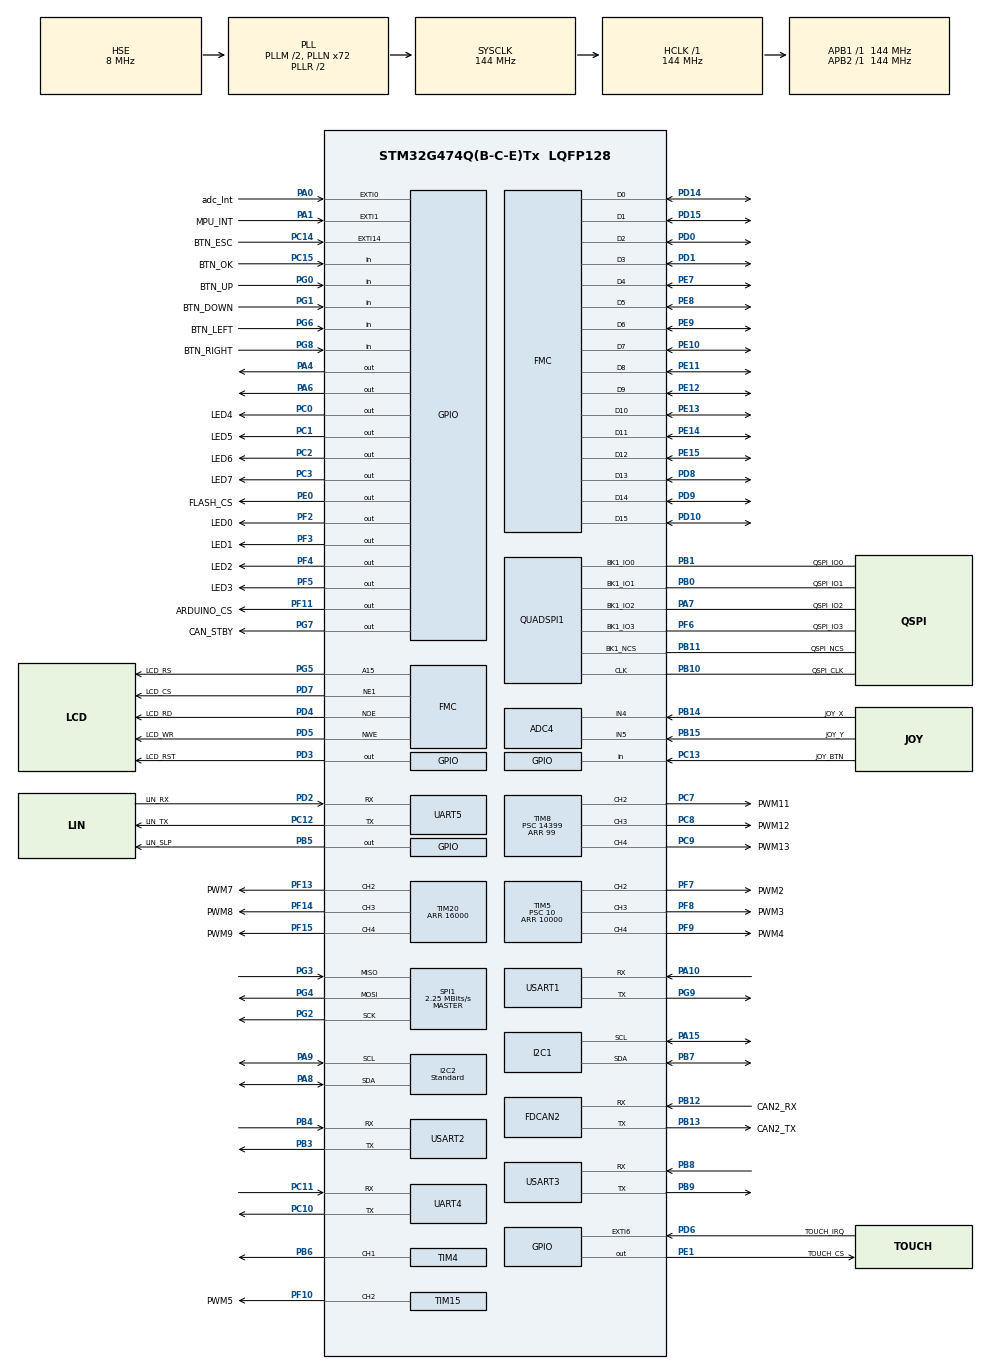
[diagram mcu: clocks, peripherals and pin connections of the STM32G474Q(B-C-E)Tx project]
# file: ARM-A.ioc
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ADC4.Channel-0\#ChannelRegularConversion=ADC_CHANNEL_4
ADC4.Channel-1\#ChannelRegularConversion=ADC_CHANNEL_5
ADC4.ClockPrescaler=ADC_CLOCK_ASYNC_DIV4
ADC4.ContinuousConvMode=DISABLE
ADC4.DMAContinuousRequests=ENABLE
ADC4.DiscontinuousConvMode=DISABLE
ADC4.EOCSelection=ADC_EOC_SINGLE_CONV
ADC4.ExternalTrigConv=ADC_EXTERNALTRIG_T1_TRGO
ADC4.NbrOfConversion=2
ADC4.NbrOfConversionFlag=1
ADC4.OffsetNumber-0\#ChannelRegularConversion=ADC_OFFSET_NONE
ADC4.OffsetNumber-1\#ChannelRegularConversion=ADC_OFFSET_NONE
ADC4.Overrun=ADC_OVR_DATA_PRESERVED
ADC4.Rank-0\#ChannelRegularConversion=1
ADC4.Rank-1\#ChannelRegularConversion=2
ADC4.SamplingTime-0\#ChannelRegularConversion=ADC_SAMPLETIME_640CYCLES_5
ADC4.SamplingTime-1\#ChannelRegularConversion=ADC_SAMPLETIME_640CYCLES_5
Dma.ADC4.2.Direction=DMA_PERIPH_TO_MEMORY
Dma.ADC4.2.EventEnable=DISABLE
Dma.ADC4.2.Instance=DMA1_Channel1
Dma.ADC4.2.MemDataAlignment=DMA_MDATAALIGN_HALFWORD
Dma.ADC4.2.MemInc=DMA_MINC_ENABLE
Dma.ADC4.2.Mode=DMA_CIRCULAR
Dma.ADC4.2.PeriphDataAlignment=DMA_PDATAALIGN_HALFWORD
Dma.ADC4.2.PeriphInc=DMA_PINC_DISABLE
Dma.ADC4.2.Polarity=HAL_DMAMUX_REQ_GEN_RISING
Dma.ADC4.2.Priority=DMA_PRIORITY_LOW
Dma.ADC4.2.RequestNumber=1
Dma.ADC4.2.SignalID=NONE
Dma.ADC4.2.SyncEnable=DISABLE
Dma.ADC4.2.SyncPolarity=HAL_DMAMUX_SYNC_NO_EVENT
Dma.ADC4.2.SyncRequestNumber=1
Dma.ADC4.2.SyncSignalID=NONE
Dma.Request0=USART1_RX
Dma.Request1=USART1_TX
Dma.Request2=ADC4
Dma.Request3=SPI1_RX
Dma.Request4=SPI1_TX
Dma.SPI1_RX.3.Direction=DMA_PERIPH_TO_MEMORY
Dma.SPI1_RX.3.EventEnable=DISABLE
Dma.SPI1_RX.3.Instance=DMA1_Channel4
Dma.SPI1_RX.3.MemDataAlignment=DMA_MDATAALIGN_BYTE
Dma.SPI1_RX.3.MemInc=DMA_MINC_ENABLE
Dma.SPI1_RX.3.Mode=DMA_NORMAL
Dma.SPI1_RX.3.PeriphDataAlignment=DMA_PDATAALIGN_BYTE
Dma.SPI1_RX.3.PeriphInc=DMA_PINC_DISABLE
Dma.SPI1_RX.3.Polarity=HAL_DMAMUX_REQ_GEN_RISING
Dma.SPI1_RX.3.Priority=DMA_PRIORITY_LOW
Dma.SPI1_RX.3.RequestNumber=1
Dma.SPI1_RX.3.SignalID=NONE
Dma.SPI1_RX.3.SyncEnable=DISABLE
Dma.SPI1_RX.3.SyncPolarity=HAL_DMAMUX_SYNC_NO_EVENT
Dma.SPI1_RX.3.SyncRequestNumber=1
Dma.SPI1_RX.3.SyncSignalID=NONE
Dma.SPI1_TX.4.Direction=DMA_MEMORY_TO_PERIPH
Dma.SPI1_TX.4.EventEnable=DISABLE
Dma.SPI1_TX.4.Instance=DMA1_Channel5
Dma.SPI1_TX.4.MemDataAlignment=DMA_MDATAALIGN_BYTE
Dma.SPI1_TX.4.MemInc=DMA_MINC_ENABLE
Dma.SPI1_TX.4.Mode=DMA_NORMAL
Dma.SPI1_TX.4.PeriphDataAlignment=DMA_PDATAALIGN_BYTE
Dma.SPI1_TX.4.PeriphInc=DMA_PINC_DISABLE
Dma.SPI1_TX.4.Polarity=HAL_DMAMUX_REQ_GEN_RISING
Dma.SPI1_TX.4.Priority=DMA_PRIORITY_LOW
Dma.SPI1_TX.4.RequestNumber=1
Dma.SPI1_TX.4.SignalID=NONE
Dma.SPI1_TX.4.SyncEnable=DISABLE
Dma.SPI1_TX.4.SyncPolarity=HAL_DMAMUX_SYNC_NO_EVENT
Dma.SPI1_TX.4.SyncRequestNumber=1
Dma.SPI1_TX.4.SyncSignalID=NONE
Dma.USART1_RX.0.Direction=DMA_PERIPH_TO_MEMORY
Dma.USART1_RX.0.EventEnable=DISABLE
Dma.USART1_RX.0.Instance=DMA1_Channel3
Dma.USART1_RX.0.MemDataAlignment=DMA_MDATAALIGN_BYTE
Dma.USART1_RX.0.MemInc=DMA_MINC_ENABLE
Dma.USART1_RX.0.Mode=DMA_NORMAL
Dma.USART1_RX.0.PeriphDataAlignment=DMA_PDATAALIGN_BYTE
Dma.USART1_RX.0.PeriphInc=DMA_PINC_DISABLE
Dma.USART1_RX.0.Polarity=HAL_DMAMUX_REQ_GEN_RISING
Dma.USART1_RX.0.Priority=DMA_PRIORITY_LOW
Dma.USART1_RX.0.RequestNumber=1
Dma.USART1_RX.0.SignalID=NONE
Dma.USART1_RX.0.SyncEnable=DISABLE
Dma.USART1_RX.0.SyncPolarity=HAL_DMAMUX_SYNC_NO_EVENT
Dma.USART1_RX.0.SyncRequestNumber=1
Dma.USART1_RX.0.SyncSignalID=NONE
Dma.USART1_TX.1.Direction=DMA_MEMORY_TO_PERIPH
Dma.USART1_TX.1.EventEnable=DISABLE
Dma.USART1_TX.1.Instance=DMA1_Channel2
Dma.USART1_TX.1.MemDataAlignment=DMA_MDATAALIGN_BYTE
Dma.USART1_TX.1.MemInc=DMA_MINC_ENABLE
Dma.USART1_TX.1.Mode=DMA_NORMAL
Dma.USART1_TX.1.PeriphDataAlignment=DMA_PDATAALIGN_BYTE
Dma.USART1_TX.1.PeriphInc=DMA_PINC_DISABLE
Dma.USART1_TX.1.Polarity=HAL_DMAMUX_REQ_GEN_RISING
Dma.USART1_TX.1.Priority=DMA_PRIORITY_LOW
Dma.USART1_TX.1.RequestNumber=1
Dma.USART1_TX.1.SignalID=NONE
Dma.USART1_TX.1.SyncEnable=DISABLE
Dma.USART1_TX.1.SyncPolarity=HAL_DMAMUX_SYNC_NO_EVENT
Dma.USART1_TX.1.SyncRequestNumber=1
Dma.USART1_TX.1.SyncSignalID=NONE
FDCAN2.CalculateBaudRateNominal=1800000
FDCAN2.CalculateTimeBitNominal=555
FDCAN2.CalculateTimeQuantumNominal=111.11111111111111
FMC.AddressSetupTime1=3
FMC.BusTurnAroundDuration1=3
FMC.DataHoldTime1=3
FMC.DataSetupTime1=3
FMC.ExtendedMode1=FMC_EXTENDED_MODE_DISABLE
I2C1.Timing=0x60715075
I2C2.I2C_Speed_Mode=I2C_Standard
I2C2.Timing=0x60715075
Mcu.Family=STM32G4
Mcu.Name=STM32G474Q(B-C-E)Tx
Mcu.Package=LQFP128
NVIC.DMA1_Channel1_IRQn=true\:0\:0\:false\:false\:true\:false\:true\:true
NVIC.DMA1_Channel2_IRQn=true\:0\:0\:false\:false\:true\:false\:true\:true
NVIC.DMA1_Channel3_IRQn=true\:0\:0\:false\:false\:true\:false\:true\:true
NVIC.DMA1_Channel4_IRQn=true\:0\:0\:false\:false\:true\:false\:true\:true
NVIC.DMA1_Channel5_IRQn=true\:0\:0\:false\:false\:true\:false\:true\:true
NVIC.EXTI0_IRQn=true\:1\:0\:true\:false\:true\:true\:true\:true
NVIC.EXTI15_10_IRQn=true\:0\:0\:true\:false\:true\:true\:true\:true
NVIC.EXTI1_IRQn=true\:1\:0\:true\:false\:true\:true\:true\:true
NVIC.EXTI9_5_IRQn=true\:0\:0\:false\:false\:true\:true\:true\:true
NVIC.PriorityGroup=NVIC_PRIORITYGROUP_4
NVIC.TIM6_DAC_IRQn=true\:0\:0\:false\:false\:true\:true\:true\:true
NVIC.USART3_IRQn=true\:0\:0\:false\:false\:true\:true\:true\:true
PA0.GPIO_Label=adc_Int
PA0.GPIO_ModeDefaultEXTI=GPIO_MODE_IT_FALLING
PA0.GPIO_PuPd=GPIO_PULLUP
PA0.Signal=GPXTI0
PA1.GPIO_Label=MPU_INT
PA1.GPIO_ModeDefaultEXTI=GPIO_MODE_IT_FALLING
PA1.Signal=GPXTI1
PA10.Mode=Asynchronous
PA10.Signal=USART1_RX
PA11.GPIO_Label=USB_MCU_N
PA11.Signal=USB_DM
PA12.GPIO_Label=USB_MCU_P
PA12.Signal=USB_DP
PA13.GPIO_Label=SWDIO
PA13.Mode=Trace_Synchro_4bits_SW
PA13.Signal=SYS_JTMS-SWDIO
PA14.GPIO_Label=SWCLK
PA14.Mode=Trace_Synchro_4bits_SW
PA14.Signal=SYS_JTCK-SWCLK
PA15.Mode=I2C
PA15.Signal=I2C1_SCL
PA2.GPIO_Label=AD2
PA2.Signal=ADC1_IN3
PA3.GPIO_Label=AD3
PA3.Signal=ADC1_IN4
PA4.Signal=GPIO_Output
PA5.GPIO_Label=AD8
PA5.Signal=ADC2_IN13
PA6.Signal=GPIO_Output
PA7.GPIO_Label=QSPI_IO2
PA7.GPIO_Speed=GPIO_SPEED_FREQ_VERY_HIGH
PA7.Mode=Single Bank 1
PA7.Signal=QUADSPI1_BK1_IO2
PA8.GPIO_Pu=GPIO_PULLUP
PA8.Mode=I2C
PA8.Signal=I2C2_SDA
PA9.GPIO_Pu=GPIO_PULLUP
PA9.Mode=I2C
PA9.Signal=I2C2_SCL
PB0.GPIO_Label=QSPI_IO1
PB0.GPIO_Speed=GPIO_SPEED_FREQ_VERY_HIGH
PB0.Mode=Single Bank 1
PB0.Signal=QUADSPI1_BK1_IO1
PB1.GPIO_Label=QSPI_IO0
PB1.GPIO_Speed=GPIO_SPEED_FREQ_VERY_HIGH
PB1.Mode=Single Bank 1
PB1.Signal=QUADSPI1_BK1_IO0
PB10.GPIO_Label=QSPI_CLK
PB10.GPIO_Speed=GPIO_SPEED_FREQ_VERY_HIGH
PB10.Mode=Single Bank 1
PB10.Signal=QUADSPI1_CLK
PB11.GPIO_Label=QSPI_NCS
PB11.GPIO_Speed=GPIO_SPEED_FREQ_VERY_HIGH
PB11.Mode=Single Bank 1
PB11.Signal=QUADSPI1_BK1_NCS
PB12.GPIO_Label=CAN2_RX
PB12.Mode=FDCAN_Activate
PB12.Signal=FDCAN2_RX
PB13.GPIO_Label=CAN2_TX
PB13.Mode=FDCAN_Activate
PB13.Signal=FDCAN2_TX
PB14.GPIO_Label=JOY_X
PB14.Mode=IN4-Single-Ended
PB14.Signal=ADC4_IN4
PB15.GPIO_Label=JOY_Y
PB15.Mode=IN5-Single-Ended
PB15.Signal=ADC4_IN5
PB3.Mode=Asynchronous
PB3.Signal=USART2_TX
PB4.Mode=Asynchronous
PB4.Signal=USART2_RX
PB5.GPIO_Label=LIN_SLP
PB5.Signal=GPIO_Output
PB6.Signal=S_TIM4_CH1
PB7.Mode=I2C
PB7.Signal=I2C1_SDA
PB8-BOOT0.Mode=Asynchronous
PB8-BOOT0.Signal=USART3_RX
PB9.Mode=Asynchronous
PB9.Signal=USART3_TX
PC0.GPIO_Label=LED4
PC0.Signal=GPIO_Output
PC1.GPIO_Label=LED5
PC1.Signal=GPIO_Output
PC10.Mode=Asynchronous
PC10.Signal=UART4_TX
PC11.Mode=Asynchronous
PC11.Signal=UART4_RX
PC12.GPIO_Label=LIN_TX
PC12.Mode=Asynchronous
PC12.Signal=UART5_TX
PC13.GPIO_Label=JOY_BTN
PC13.GPIO_PuPd=GPIO_PULLUP
PC13.Signal=GPIO_Input
PC14-OSC32_IN.GPIO_Label=BTN_ESC
PC14-OSC32_IN.GPIO_ModeDefaultEXTI=GPIO_MODE_IT_FALLING
PC14-OSC32_IN.GPIO_PuPd=GPIO_PULLUP
PC14-OSC32_IN.Signal=GPXTI14
PC15-OSC32_OUT.GPIO_Label=BTN_OK
PC15-OSC32_OUT.GPIO_PuPd=GPIO_PULLUP
PC15-OSC32_OUT.Signal=GPIO_Input
PC2.GPIO_Label=LED6
PC2.Signal=GPIO_Output
PC3.GPIO_Label=LED7
PC3.Signal=GPIO_Output
PC4.GPIO_Label=AD4
PC4.Signal=ADC2_IN5
PC5.GPIO_Label=AD6
PC5.Signal=ADC2_IN11
PC7.GPIO_Label=PWM11
PC7.Signal=S_TIM8_CH2
PC8.GPIO_Label=PWM12
PC8.Signal=S_TIM8_CH3
PC9.GPIO_Label=PWM13
PC9.Signal=S_TIM8_CH4
PD0.Signal=FMC_D2_DA2
PD1.Signal=FMC_D3_DA3
PD10.Signal=FMC_D15_DA15
PD11.GPIO_Label=AD9
PD11.GPIO_Mode=GPIO_MODE_ANALOG
PD11.GPIO_PuPd=GPIO_NOPULL
PD11.Signal=ADC3_IN8
PD12.GPIO_Label=AD10
PD12.GPIO_Mode=GPIO_MODE_ANALOG
PD12.GPIO_PuPd=GPIO_NOPULL
PD12.Signal=ADC3_IN9
PD13.GPIO_Label=AD11
PD13.GPIO_Mode=GPIO_MODE_ANALOG
PD13.GPIO_PuPd=GPIO_NOPULL
PD13.Signal=ADC3_IN10
PD14.Signal=FMC_D0_DA0
PD15.Signal=FMC_D1_DA1
PD2.GPIO_Label=LIN_RX
PD2.Mode=Asynchronous
PD2.Signal=UART5_RX
PD3.GPIO_Label=LCD_RST
PD3.Signal=GPIO_Output
PD4.GPIO_Label=LCD_RD
PD4.Signal=FMC_NOE
PD5.GPIO_Label=LCD_WR
PD5.Signal=FMC_NWE
PD6.GPIO_Label=TOUCH_IRQ
PD6.GPIO_ModeDefaultEXTI=GPIO_MODE_IT_FALLING
PD6.GPIO_PuPd=GPIO_PULLUP
PD6.Signal=GPXTI6
PD7.GPIO_Label=LCD_CS
PD7.Mode=NorPsramChipSelect1_1
PD7.Signal=FMC_NE1
PD8.Signal=FMC_D13_DA13
PD9.Signal=FMC_D14_DA14
PE0.GPIO_Label=FLASH_CS
PE0.Signal=GPIO_Output
PE1.GPIO_Label=TOUCH_CS
PE1.GPIO_PuPd=GPIO_PULLUP
PE1.GPIO_Speed=GPIO_SPEED_FREQ_HIGH
PE1.PinState=GPIO_PIN_SET
PE1.Signal=GPIO_Output
PE10.Signal=FMC_D7_DA7
PE11.Signal=FMC_D8_DA8
PE12.Signal=FMC_D9_DA9
PE13.Signal=FMC_D10_DA10
PE14.Signal=FMC_D11_DA11
PE15.Signal=FMC_D12_DA12
PE2.Mode=Trace_Synchro_4bits_SW
PE2.Signal=SYS_TRACECLK
PE3.Mode=Trace_Synchro_4bits_SW
PE3.Signal=SYS_TRACED0
PE4.Mode=Trace_Synchro_4bits_SW
PE4.Signal=SYS_TRACED1
PE5.Mode=Trace_Synchro_4bits_SW
PE5.Signal=SYS_TRACED2
PE6.Mode=Trace_Synchro_4bits_SW
PE6.Signal=SYS_TRACED3
PE7.Signal=FMC_D4_DA4
PE8.Signal=FMC_D5_DA5
PE9.Signal=FMC_D6_DA6
PF0-OSC_IN.GPIO_Label=MCI
PF0-OSC_IN.Mode=HSE-External-Clock-Source
PF0-OSC_IN.Signal=RCC_OSC_IN
PF1-OSC_OUT.GPIO_Label=AD5
PF1-OSC_OUT.Signal=ADC2_IN10
PF10.GPIO_Label=PWM5
PF10.Signal=S_TIM15_CH2
PF11.GPIO_Label=ARDUINO_CS
PF11.Signal=GPIO_Output
PF12.GPIO_Label=PWM6
PF12.Signal=S_TIM20_CH1
PF13.GPIO_Label=PWM7
PF13.Signal=S_TIM20_CH2
PF14.GPIO_Label=PWM8
PF14.Signal=S_TIM20_CH3
PF15.GPIO_Label=PWM9
PF15.Signal=S_TIM20_CH4
PF2.GPIO_Label=LED0
PF2.GPIO_Speed=GPIO_SPEED_FREQ_VERY_HIGH
PF2.Signal=GPIO_Output
PF3.GPIO_Label=LED1
PF3.Signal=GPIO_Output
PF4.GPIO_Label=LED2
PF4.Signal=GPIO_Output
PF5.GPIO_Label=LED3
PF5.Signal=GPIO_Output
PF6.GPIO_Label=QSPI_IO3
PF6.GPIO_Speed=GPIO_SPEED_FREQ_VERY_HIGH
PF6.Mode=Single Bank 1
PF6.Signal=QUADSPI1_BK1_IO3
PF7.GPIO_Label=PWM2
PF7.Signal=S_TIM5_CH2
PF8.GPIO_Label=PWM3
PF8.Signal=S_TIM5_CH3
PF9.GPIO_Label=PWM4
PF9.Signal=S_TIM5_CH4
PG0.GPIO_Label=BTN_UP
PG0.GPIO_PuPd=GPIO_PULLUP
PG0.Signal=GPIO_Input
PG1.GPIO_Label=BTN_DOWN
PG1.GPIO_PuPd=GPIO_PULLUP
PG1.Signal=GPIO_Input
PG2.Mode=Full_Duplex_Master
PG2.Signal=SPI1_SCK
PG3.Mode=Full_Duplex_Master
PG3.Signal=SPI1_MISO
PG4.Mode=Full_Duplex_Master
PG4.Signal=SPI1_MOSI
PG5.GPIO_Label=LCD_RS
PG5.Signal=FMC_A15
PG6.GPIO_Label=BTN_LEFT
PG6.GPIO_PuPd=GPIO_PULLUP
PG6.Signal=GPIO_Input
PG7.GPIO_Label=CAN_STBY
PG7.Signal=GPIO_Output
PG8.GPIO_Label=BTN_RIGHT
PG8.GPIO_PuPd=GPIO_PULLUP
PG8.Signal=GPIO_Input
PG9.Mode=Asynchronous
PG9.Signal=USART1_TX
ProjectManager.HeapSize=0x200
ProjectManager.StackSize=0x400
ProjectManager.TargetToolchain=STM32CubeIDE
QUADSPI1.ChipSelectHighTime=QSPI_CS_HIGH_TIME_6_CYCLE
QUADSPI1.FifoThreshold=4
QUADSPI1.FlashSize=23
QUADSPI1.SampleShifting=QSPI_SAMPLE_SHIFTING_HALFCYCLE
RCC.ADC12Freq_Value=144000000
RCC.ADC345Freq_Value=144000000
RCC.AHBFreq_Value=144000000
RCC.APB1Freq_Value=144000000
RCC.APB1TimFreq_Value=144000000
RCC.APB2Freq_Value=144000000
RCC.APB2TimFreq_Value=144000000
RCC.CortexFreq_Value=144000000
RCC.EXTERNAL_CLOCK_VALUE=12288000
RCC.HCLKFreq_Value=144000000
RCC.HSE_VALUE=8000000
RCC.HSI48_VALUE=48000000
RCC.HSI_VALUE=16000000
RCC.LSE_VALUE=32768
RCC.PLLM=RCC_PLLM_DIV2
RCC.PLLN=72
RCC.PLLQ=RCC_PLLQ_DIV6
RCC.PLLSourceVirtual=RCC_PLLSOURCE_HSE
RCC.SYSCLKFreq_VALUE=144000000
RCC.SYSCLKSource=RCC_SYSCLKSOURCE_PLLCLK
RCC.USBFreq_Value=48000000
RCC.VCOOutputFreq_Value=288000000
SH.FMC_A15.0=FMC_A15,A15_1
SH.FMC_D0_DA0.0=FMC_D0,16b-d1
SH.FMC_D10_DA10.0=FMC_D10,16b-d1
SH.FMC_D11_DA11.0=FMC_D11,16b-d1
SH.FMC_D12_DA12.0=FMC_D12,16b-d1
SH.FMC_D13_DA13.0=FMC_D13,16b-d1
SH.FMC_D14_DA14.0=FMC_D14,16b-d1
SH.FMC_D15_DA15.0=FMC_D15,16b-d1
SH.FMC_D1_DA1.0=FMC_D1,16b-d1
SH.FMC_D2_DA2.0=FMC_D2,16b-d1
SH.FMC_D3_DA3.0=FMC_D3,16b-d1
SH.FMC_D4_DA4.0=FMC_D4,16b-d1
SH.FMC_D5_DA5.0=FMC_D5,16b-d1
SH.FMC_D6_DA6.0=FMC_D6,16b-d1
SH.FMC_D7_DA7.0=FMC_D7,16b-d1
SH.FMC_D8_DA8.0=FMC_D8,16b-d1
SH.FMC_D9_DA9.0=FMC_D9,16b-d1
SH.FMC_NOE.0=FMC_NOE,Lcd1
SH.FMC_NWE.0=FMC_NWE,Lcd1
SH.S_TIM15_CH2.0=TIM15_CH2,PWM Generation2 CH2
SH.S_TIM20_CH1.0=TIM20_CH1
SH.S_TIM20_CH2.0=TIM20_CH2,PWM Generation2 CH2
SH.S_TIM20_CH3.0=TIM20_CH3,PWM Generation3 CH3
SH.S_TIM20_CH4.0=TIM20_CH4,PWM Generation4 CH4
SH.S_TIM4_CH1.0=TIM4_CH1,PWM Generation1 CH1
SH.S_TIM5_CH2.0=TIM5_CH2,PWM Generation2 CH2
SH.S_TIM5_CH3.0=TIM5_CH3,PWM Generation3 CH3
SH.S_TIM5_CH4.0=TIM5_CH4,PWM Generation4 CH4
SH.S_TIM8_CH2.0=TIM8_CH2,PWM Generation2 CH2
SH.S_TIM8_CH3.0=TIM8_CH3,PWM Generation3 CH3
SH.S_TIM8_CH4.0=TIM8_CH4,PWM Generation4 CH4
SPI1.BaudRatePrescaler=SPI_BAUDRATEPRESCALER_64
SPI1.CalculateBaudRate=2.25 MBits/s
SPI1.DataSize=SPI_DATASIZE_8BIT
SPI1.Direction=SPI_DIRECTION_2LINES
SPI1.Mode=SPI_MODE_MASTER
SPI1.NSSPMode=SPI_NSS_PULSE_DISABLE
SPI1.VirtualType=VM_MASTER
STMicroelectronics.X-CUBE-DISPLAY.2.0.0.BSP.number=2
STMicroelectronics.X-CUBE-DISPLAY.2.0.0.p_display_cache_lines=4
STMicroelectronics.X-CUBE-DISPLAY.2.0.0.p_fmc_dma_tx_id=1\:1
STMicroelectronics.X-CUBE-DISPLAY.2.0.00.BSP.STBoard=false
STMicroelectronics.X-CUBE-DISPLAY.2.0.00.BSP.api=Unknown
STMicroelectronics.X-CUBE-DISPLAY.2.0.00.BSP.condition=(SEMBoardOoPartJjLCDJjILI9341JjSPI | SEMBoardOoPartJjLCDJjILI9341JjFMC)
STMicroelectronics.X-CUBE-DISPLAY.2.0.00.BSP.instance=PD3
STMicroelectronics.X-CUBE-DISPLAY.2.0.00.BSP.ip=GPIO
STMicroelectronics.X-CUBE-DISPLAY.2.0.00.BSP.mode=Output
STMicroelectronics.X-CUBE-DISPLAY.2.0.00.BSP.name=LCD RESET Pin
STMicroelectronics.X-CUBE-DISPLAY.2.0.00.BSP.solution=PD3
STMicroelectronics.X-CUBE-DISPLAY.2.0.01.BSP.STBoard=false
STMicroelectronics.X-CUBE-DISPLAY.2.0.01.BSP.api=HAL_EXTI_DRIVER
STMicroelectronics.X-CUBE-DISPLAY.2.0.01.BSP.condition=(SEMBoardOoPartJjLCDJjILI9341JjSPI | SEMBoardOoPartJjLCDJjILI9341JjFMC)
STMicroelectronics.X-CUBE-DISPLAY.2.0.01.BSP.instance=PC14-OSC32_IN
STMicroelectronics.X-CUBE-DISPLAY.2.0.01.BSP.ip=GPIO
STMicroelectronics.X-CUBE-DISPLAY.2.0.01.BSP.mode=EXTI
STMicroelectronics.X-CUBE-DISPLAY.2.0.01.BSP.name=LCD TE Pin
STMicroelectronics.X-CUBE-DISPLAY.2.0.01.BSP.solution=PC14-OSC32_IN
STMicroelectronics.X-CUBE-TOUCHGFX.4.18.0.tgfx_buffering_strategy=Partial
STMicroelectronics.X-CUBE-TOUCHGFX.4.18.0.tgfx_custom_height=240
STMicroelectronics.X-CUBE-TOUCHGFX.4.18.0.tgfx_custom_width=320
STMicroelectronics.X-CUBE-TOUCHGFX.4.18.0.tgfx_display_interface=disp_fmc
STMicroelectronics.X-CUBE-TOUCHGFX.4.18.0.tgfx_hardware_accelerator=dma_none
STMicroelectronics.X-CUBE-TOUCHGFX.4.18.0_IsPackSelfContextualization=true
TIM1.PeriodNoDither=9999
TIM1.Prescaler=144
TIM1.TIM_MasterOutputTrigger=TIM_TRGO_UPDATE
TIM15.Channel-PWM\ Generation2\ CH2=TIM_CHANNEL_2
TIM15.PeriodNoDither=32768
TIM15.PulseNoDither_2=16000
TIM20.Channel-PWM\ Generation1\ CH1=TIM_CHANNEL_1
TIM20.Channel-PWM\ Generation2\ CH2=TIM_CHANNEL_2
TIM20.Channel-PWM\ Generation3\ CH3=TIM_CHANNEL_3
TIM20.Channel-PWM\ Generation4\ CH4=TIM_CHANNEL_4
TIM20.PeriodNoDither=16000
TIM20.PulseNoDither_1=8000
TIM20.PulseNoDither_2=10000
TIM20.PulseNoDither_3=12000
TIM20.PulseNoDither_4=15000
TIM4.Channel-PWM\ Generation1\ CH1=TIM_CHANNEL_1
TIM4.OC1Preload_PWM=DISABLE
TIM4.OCPolarity_1=TIM_OCPOLARITY_LOW
TIM4.PeriodNoDither=99
TIM4.Prescaler=14399
TIM4.PulseNoDither_1=50
TIM5.AutoReloadPreload=TIM_AUTORELOAD_PRELOAD_ENABLE
TIM5.Channel-PWM\ Generation2\ CH2=TIM_CHANNEL_2
TIM5.Channel-PWM\ Generation3\ CH3=TIM_CHANNEL_3
TIM5.Channel-PWM\ Generation4\ CH4=TIM_CHANNEL_4
TIM5.PeriodNoDither=10000
TIM5.Prescaler=10
TIM5.PulseNoDither_2=200
TIM5.PulseNoDither_3=400
TIM5.PulseNoDither_4=600
TIM6.AutoReloadPreload=TIM_AUTORELOAD_PRELOAD_ENABLE
TIM6.PeriodNoDither=49999
TIM6.Prescaler=170
TIM8.Channel-PWM\ Generation2\ CH2=TIM_CHANNEL_2
TIM8.Channel-PWM\ Generation3\ CH3=TIM_CHANNEL_3
TIM8.Channel-PWM\ Generation4\ CH4=TIM_CHANNEL_4
TIM8.PeriodNoDither=99
TIM8.Prescaler=14399
TIM8.PulseNoDither_2=2000
TIM8.PulseNoDither_3=4000
TIM8.PulseNoDither_4=8000
USART1.VirtualMode-Asynchronous=VM_ASYNC
USART2.VirtualMode-Asynchronous=VM_ASYNC
USART3.VirtualMode-Asynchronous=VM_ASYNC
VP_CORDIC_VS_CORDIC.Mode=CORDIC_Activate
VP_SYS_VS_DBSignals.Mode=DisableDeadBatterySignals
VP_TIM15_VS_ClockSourceINT.Mode=Internal
VP_TIM1_VS_ClockSourceINT.Mode=Internal
VP_TIM20_VS_ClockSourceINT.Mode=Internal
VP_TIM4_VS_ClockSourceINT.Mode=Internal
VP_TIM5_VS_ClockSourceINT.Mode=Internal
VP_TIM6_VS_ClockSourceINT.Mode=Enable_Timer
VP_TIM8_VS_ClockSourceINT.Mode=Internal
board=custom

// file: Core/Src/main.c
/* USER CODE BEGIN Header */
/**
  ******************************************************************************
  * @file           : main.c
  * @brief          : Main program body
  ******************************************************************************
  * @attention
  *
  * Copyright (c) 2022 STMicroelectronics.
  * All rights reserved.
  *
  * This software is licensed under terms that can be found in the LICENSE file
  * in the root directory of this software component.
  * If no LICENSE file comes with this software, it is provided AS-IS.
  *
  ******************************************************************************
  */
/* USER CODE END Header */
#include "main.h"

/* USER CODE BEGIN Includes */
#include "pca9685.h"
#include "LED.h"
#include "kbd.h"
#include "SCI.h"
#include "lcd.h"
#include "timing_utils.h"
#include "periodic_services.h"
#include "lcd_backlight.h"
#include "XPT2046_touch.h"
#include "3DEngine.h"
#include "joystick.h"
#include "mcp3464.h"
#include "mpu6050.h"
/* USER CODE END Includes */

 ADC_HandleTypeDef hadc4;
DMA_HandleTypeDef hdma_adc4;

CORDIC_HandleTypeDef hcordic;

FDCAN_HandleTypeDef hfdcan2;

I2C_HandleTypeDef hi2c1;
I2C_HandleTypeDef hi2c2;

QSPI_HandleTypeDef hqspi1;

SPI_HandleTypeDef hspi1;
DMA_HandleTypeDef hdma_spi1_rx;
DMA_HandleTypeDef hdma_spi1_tx;

TIM_HandleTypeDef htim1;
TIM_HandleTypeDef htim4;
TIM_HandleTypeDef htim5;
TIM_HandleTypeDef htim6;
TIM_HandleTypeDef htim15;
TIM_HandleTypeDef htim20;

UART_HandleTypeDef huart4;
UART_HandleTypeDef huart5;
UART_HandleTypeDef huart1;
UART_HandleTypeDef huart2;
DMA_HandleTypeDef hdma_usart1_rx;
DMA_HandleTypeDef hdma_usart1_tx;

SRAM_HandleTypeDef hsram1;

void SystemClock_Config(void);
static void MX_GPIO_Init(void);
static void MX_FMC_Init(void);
static void MX_UART4_Init(void);
static void MX_UART5_Init(void);
static void MX_USART1_UART_Init(void);
static void MX_USART2_UART_Init(void);
static void MX_QUADSPI1_Init(void);
static void MX_SPI1_Init(void);
static void MX_TIM5_Init(void);
static void MX_TIM8_Init(void);
static void MX_TIM20_Init(void);
static void MX_FDCAN2_Init(void);
static void MX_I2C1_Init(void);
static void MX_TIM15_Init(void);
static void MX_USART3_UART_Init(void);
static void MX_ADC4_Init(void);
static void MX_DMA_Init(void);
static void MX_TIM6_Init(void);
static void MX_CORDIC_Init(void);
static void MX_TIM1_Init(void);
static void MX_TIM4_Init(void);

int main(void)
{

  /* MCU Configuration--------------------------------------------------------*/

  /* Reset of all peripherals, Initializes the Flash interface and the Systick. */
  HAL_Init();

  /* Configure the system clock */
  SystemClock_Config();

  /* Initialize all configured peripherals */
  MX_GPIO_Init();
  MX_FMC_Init();
  MX_I2C2_Init();
  MX_UART4_Init();
  MX_UART5_Init();
  MX_USART1_UART_Init();
  MX_USART2_UART_Init();
  MX_QUADSPI1_Init();
  MX_SPI1_Init();
  MX_TIM5_Init();
  MX_TIM8_Init();
  MX_TIM20_Init();
  MX_FDCAN2_Init();
  MX_I2C1_Init();
  MX_TIM15_Init();
  MX_USART3_UART_Init();
  MX_DMA_Init();
  MX_TIM6_Init();
  MX_CORDIC_Init();
  MX_TIM1_Init();
  MX_TIM4_Init();
  /* USER CODE BEGIN 2 */
  MX_ADC4_Init();
  MX_SPI1_Init();

  LED_init();
  KBD_init();
  SCI_init();
  SCI_demo_Hello_world();
  LCD_BKLT_init();
  LCD_Init();
  PSERV_init();
  PSERV_enable();
  MCP_init();
  MPU6050_Init();

  MPU6050_Calc_Offsets(1, 1);
  MCP3464_Calibrate();

  Init_3D();

  /* USER CODE END 2 */

  /* Infinite loop */
  while (1)
  {

  }
}

void SystemClock_Config(void)
{
  RCC_OscInitTypeDef RCC_OscInitStruct = {0};
  RCC_ClkInitTypeDef RCC_ClkInitStruct = {0};

  /** Configure the main internal regulator output voltage
  */
  HAL_PWREx_ControlVoltageScaling(PWR_REGULATOR_VOLTAGE_SCALE1);

  /** Initializes the RCC Oscillators according to the specified parameters
  * in the RCC_OscInitTypeDef structure.
  */
  RCC_OscInitStruct.OscillatorType = RCC_OSCILLATORTYPE_HSE;
  RCC_OscInitStruct.HSEState = RCC_HSE_BYPASS;
  RCC_OscInitStruct.PLL.PLLState = RCC_PLL_ON;
  RCC_OscInitStruct.PLL.PLLSource = RCC_PLLSOURCE_HSE;
  RCC_OscInitStruct.PLL.PLLM = RCC_PLLM_DIV2;
  RCC_OscInitStruct.PLL.PLLN = 72;
  RCC_OscInitStruct.PLL.PLLP = RCC_PLLP_DIV2;
  RCC_OscInitStruct.PLL.PLLQ = RCC_PLLQ_DIV6;
  RCC_OscInitStruct.PLL.PLLR = RCC_PLLR_DIV2;
  if (HAL_RCC_OscConfig(&RCC_OscInitStruct) != HAL_OK)
  {
    Error_Handler();
  }

  /** Initializes the CPU, AHB and APB buses clocks
  */
  RCC_ClkInitStruct.ClockType = RCC_CLOCKTYPE_HCLK|RCC_CLOCKTYPE_SYSCLK
                              |RCC_CLOCKTYPE_PCLK1|RCC_CLOCKTYPE_PCLK2;
  RCC_ClkInitStruct.SYSCLKSource = RCC_SYSCLKSOURCE_PLLCLK;
  RCC_ClkInitStruct.AHBCLKDivider = RCC_SYSCLK_DIV1;
  RCC_ClkInitStruct.APB1CLKDivider = RCC_HCLK_DIV1;
  RCC_ClkInitStruct.APB2CLKDivider = RCC_HCLK_DIV1;

  if (HAL_RCC_ClockConfig(&RCC_ClkInitStruct, FLASH_LATENCY_4) != HAL_OK)
  {
    Error_Handler();
  }
}

static void MX_ADC4_Init(void)
{

  ADC_ChannelConfTypeDef sConfig = {0};

  /** Common config
  */
  hadc4.Instance = ADC4;
  hadc4.Init.ClockPrescaler = ADC_CLOCK_ASYNC_DIV4;
  hadc4.Init.Resolution = ADC_RESOLUTION_12B;
  hadc4.Init.DataAlign = ADC_DATAALIGN_RIGHT;
  hadc4.Init.GainCompensation = 0;
  hadc4.Init.ScanConvMode = ADC_SCAN_ENABLE;
  hadc4.Init.EOCSelection = ADC_EOC_SINGLE_CONV;
  hadc4.Init.LowPowerAutoWait = DISABLE;
  hadc4.Init.ContinuousConvMode = DISABLE;
  hadc4.Init.NbrOfConversion = 2;
  hadc4.Init.DiscontinuousConvMode = DISABLE;
  hadc4.Init.ExternalTrigConv = ADC_EXTERNALTRIG_T1_TRGO;
  hadc4.Init.ExternalTrigConvEdge = ADC_EXTERNALTRIGCONVEDGE_RISING;
  hadc4.Init.DMAContinuousRequests = ENABLE;
  hadc4.Init.Overrun = ADC_OVR_DATA_PRESERVED;
  hadc4.Init.OversamplingMode = DISABLE;
  if (HAL_ADC_Init(&hadc4) != HAL_OK)
  {
    Error_Handler();
  }

  /** Configure Regular Channel
  */
  sConfig.Channel = ADC_CHANNEL_4;
  sConfig.Rank = ADC_REGULAR_RANK_1;
  sConfig.SamplingTime = ADC_SAMPLETIME_640CYCLES_5;
  sConfig.SingleDiff = ADC_SINGLE_ENDED;
  sConfig.OffsetNumber = ADC_OFFSET_NONE;
  sConfig.Offset = 0;
  if (HAL_ADC_ConfigChannel(&hadc4, &sConfig) != HAL_OK)
  {
    Error_Handler();
  }

  /** Configure Regular Channel
  */
  sConfig.Channel = ADC_CHANNEL_5;
  sConfig.Rank = ADC_REGULAR_RANK_2;
  if (HAL_ADC_ConfigChannel(&hadc4, &sConfig) != HAL_OK)
  {
    Error_Handler();
  }

}

static void MX_CORDIC_Init(void)
{

  hcordic.Instance = CORDIC;
  if (HAL_CORDIC_Init(&hcordic) != HAL_OK)
  {
    Error_Handler();
  }

}

static void MX_FDCAN2_Init(void)
{

  hfdcan2.Instance = FDCAN2;
  hfdcan2.Init.ClockDivider = FDCAN_CLOCK_DIV1;
  hfdcan2.Init.FrameFormat = FDCAN_FRAME_CLASSIC;
  hfdcan2.Init.Mode = FDCAN_MODE_NORMAL;
  hfdcan2.Init.AutoRetransmission = DISABLE;
  hfdcan2.Init.TransmitPause = DISABLE;
  hfdcan2.Init.ProtocolException = DISABLE;
  hfdcan2.Init.NominalPrescaler = 1;
  hfdcan2.Init.NominalSyncJumpWidth = 1;
  hfdcan2.Init.NominalTimeSeg1 = 2;
  hfdcan2.Init.NominalTimeSeg2 = 2;
  hfdcan2.Init.DataPrescaler = 1;
  hfdcan2.Init.DataSyncJumpWidth = 1;
  hfdcan2.Init.DataTimeSeg1 = 1;
  hfdcan2.Init.DataTimeSeg2 = 1;
  hfdcan2.Init.StdFiltersNbr = 0;
  hfdcan2.Init.ExtFiltersNbr = 0;
  hfdcan2.Init.TxFifoQueueMode = FDCAN_TX_FIFO_OPERATION;
  if (HAL_FDCAN_Init(&hfdcan2) != HAL_OK)
  {
    Error_Handler();
  }

}

static void MX_I2C1_Init(void)
{

  hi2c1.Instance = I2C1;
  hi2c1.Init.Timing = 0x20B0D9FF;
  hi2c1.Init.OwnAddress1 = 0;
  hi2c1.Init.AddressingMode = I2C_ADDRESSINGMODE_7BIT;
  hi2c1.Init.DualAddressMode = I2C_DUALADDRESS_DISABLE;
  hi2c1.Init.OwnAddress2 = 0;
  hi2c1.Init.OwnAddress2Masks = I2C_OA2_NOMASK;
  hi2c1.Init.GeneralCallMode = I2C_GENERALCALL_DISABLE;
  hi2c1.Init.NoStretchMode = I2C_NOSTRETCH_DISABLE;
  if (HAL_I2C_Init(&hi2c1) != HAL_OK)
  {
    Error_Handler();
  }

  /** Configure Analogue filter
  */
  if (HAL_I2CEx_ConfigAnalogFilter(&hi2c1, I2C_ANALOGFILTER_ENABLE) != HAL_OK)
  {
    Error_Handler();
  }

  /** Configure Digital filter
  */
  if (HAL_I2CEx_ConfigDigitalFilter(&hi2c1, 0) != HAL_OK)
  {
    Error_Handler();
  }

}

void MX_I2C2_Init(void)
{

  hi2c2.Instance = I2C2;
  hi2c2.Init.Timing = 0x00E057FD;
  hi2c2.Init.OwnAddress1 = 0;
  hi2c2.Init.AddressingMode = I2C_ADDRESSINGMODE_7BIT;
  hi2c2.Init.DualAddressMode = I2C_DUALADDRESS_DISABLE;
  hi2c2.Init.OwnAddress2 = 0;
  hi2c2.Init.OwnAddress2Masks = I2C_OA2_NOMASK;
  hi2c2.Init.GeneralCallMode = I2C_GENERALCALL_DISABLE;
  hi2c2.Init.NoStretchMode = I2C_NOSTRETCH_DISABLE;
  if (HAL_I2C_Init(&hi2c2) != HAL_OK)
  {
    Error_Handler();
  }

  /** Configure Analogue filter
  */
  if (HAL_I2CEx_ConfigAnalogFilter(&hi2c2, I2C_ANALOGFILTER_ENABLE) != HAL_OK)
  {
    Error_Handler();
  }

  /** Configure Digital filter
  */
  if (HAL_I2CEx_ConfigDigitalFilter(&hi2c2, 0) != HAL_OK)
  {
    Error_Handler();
  }

}

static void MX_QUADSPI1_Init(void)
{

  /* QUADSPI1 parameter configuration*/
  hqspi1.Instance = QUADSPI;
  hqspi1.Init.ClockPrescaler = 255;
  hqspi1.Init.FifoThreshold = 4;
  hqspi1.Init.SampleShifting = QSPI_SAMPLE_SHIFTING_HALFCYCLE;
  hqspi1.Init.FlashSize = 23;
  hqspi1.Init.ChipSelectHighTime = QSPI_CS_HIGH_TIME_6_CYCLE;
  hqspi1.Init.ClockMode = QSPI_CLOCK_MODE_0;
  hqspi1.Init.FlashID = QSPI_FLASH_ID_1;
  hqspi1.Init.DualFlash = QSPI_DUALFLASH_DISABLE;
  if (HAL_QSPI_Init(&hqspi1) != HAL_OK)
  {
    Error_Handler();
  }

}

static void MX_SPI1_Init(void)
{

  /* SPI1 parameter configuration*/
  hspi1.Instance = SPI1;
  hspi1.Init.Mode = SPI_MODE_MASTER;
  hspi1.Init.Direction = SPI_DIRECTION_2LINES;
  hspi1.Init.DataSize = SPI_DATASIZE_8BIT;
  hspi1.Init.CLKPolarity = SPI_POLARITY_LOW;
  hspi1.Init.CLKPhase = SPI_PHASE_1EDGE;
  hspi1.Init.NSS = SPI_NSS_SOFT;
  hspi1.Init.BaudRatePrescaler = SPI_BAUDRATEPRESCALER_64;
  hspi1.Init.FirstBit = SPI_FIRSTBIT_MSB;
  hspi1.Init.TIMode = SPI_TIMODE_DISABLE;
  hspi1.Init.CRCCalculation = SPI_CRCCALCULATION_DISABLE;
  hspi1.Init.CRCPolynomial = 7;
  hspi1.Init.CRCLength = SPI_CRC_LENGTH_DATASIZE;
  hspi1.Init.NSSPMode = SPI_NSS_PULSE_DISABLE;
  if (HAL_SPI_Init(&hspi1) != HAL_OK)
  {
    Error_Handler();
  }

}

static void MX_TIM1_Init(void)
{

  TIM_ClockConfigTypeDef sClockSourceConfig = {0};
  TIM_MasterConfigTypeDef sMasterConfig = {0};

  htim1.Instance = TIM1;
  htim1.Init.Prescaler = 144;
  htim1.Init.CounterMode = TIM_COUNTERMODE_UP;
  htim1.Init.Period = 9999;
  htim1.Init.ClockDivision = TIM_CLOCKDIVISION_DIV1;
  htim1.Init.RepetitionCounter = 0;
  htim1.Init.AutoReloadPreload = TIM_AUTORELOAD_PRELOAD_DISABLE;
  if (HAL_TIM_Base_Init(&htim1) != HAL_OK)
  {
    Error_Handler();
  }
  sClockSourceConfig.ClockSource = TIM_CLOCKSOURCE_INTERNAL;
  if (HAL_TIM_ConfigClockSource(&htim1, &sClockSourceConfig) != HAL_OK)
  {
    Error_Handler();
  }
  sMasterConfig.MasterOutputTrigger = TIM_TRGO_UPDATE;
  sMasterConfig.MasterOutputTrigger2 = TIM_TRGO2_RESET;
  sMasterConfig.MasterSlaveMode = TIM_MASTERSLAVEMODE_DISABLE;
  if (HAL_TIMEx_MasterConfigSynchronization(&htim1, &sMasterConfig) != HAL_OK)
  {
    Error_Handler();
  }

}

static void MX_TIM4_Init(void)
{

  TIM_ClockConfigTypeDef sClockSourceConfig = {0};
  TIM_MasterConfigTypeDef sMasterConfig = {0};
  TIM_OC_InitTypeDef sConfigOC = {0};

  htim4.Instance = TIM4;
  htim4.Init.Prescaler = 14399;
  htim4.Init.CounterMode = TIM_COUNTERMODE_UP;
  htim4.Init.Period = 99;
  htim4.Init.ClockDivision = TIM_CLOCKDIVISION_DIV1;
  htim4.Init.AutoReloadPreload = TIM_AUTORELOAD_PRELOAD_DISABLE;
  if (HAL_TIM_Base_Init(&htim4) != HAL_OK)
  {
    Error_Handler();
  }
  sClockSourceConfig.ClockSource = TIM_CLOCKSOURCE_INTERNAL;
  if (HAL_TIM_ConfigClockSource(&htim4, &sClockSourceConfig) != HAL_OK)
  {
    Error_Handler();
  }
  if (HAL_TIM_PWM_Init(&htim4) != HAL_OK)
  {
    Error_Handler();
  }
  sMasterConfig.MasterOutputTrigger = TIM_TRGO_RESET;
  sMasterConfig.MasterSlaveMode = TIM_MASTERSLAVEMODE_DISABLE;
  if (HAL_TIMEx_MasterConfigSynchronization(&htim4, &sMasterConfig) != HAL_OK)
  {
    Error_Handler();
  }
  sConfigOC.OCMode = TIM_OCMODE_PWM1;
  sConfigOC.Pulse = 50;
  sConfigOC.OCPolarity = TIM_OCPOLARITY_LOW;
  sConfigOC.OCFastMode = TIM_OCFAST_DISABLE;
  if (HAL_TIM_PWM_ConfigChannel(&htim4, &sConfigOC, TIM_CHANNEL_1) != HAL_OK)
  {
    Error_Handler();
  }
  __HAL_TIM_DISABLE_OCxPRELOAD(&htim4, TIM_CHANNEL_1);
  HAL_TIM_MspPostInit(&htim4);

}

static void MX_TIM5_Init(void)
{

  TIM_ClockConfigTypeDef sClockSourceConfig = {0};
  TIM_MasterConfigTypeDef sMasterConfig = {0};
  TIM_OC_InitTypeDef sConfigOC = {0};

  htim5.Instance = TIM5;
  htim5.Init.Prescaler = 10;
  htim5.Init.CounterMode = TIM_COUNTERMODE_UP;
  htim5.Init.Period = 10000;
  htim5.Init.ClockDivision = TIM_CLOCKDIVISION_DIV1;
  htim5.Init.AutoReloadPreload = TIM_AUTORELOAD_PRELOAD_ENABLE;
  if (HAL_TIM_Base_Init(&htim5) != HAL_OK)
  {
    Error_Handler();
  }
  sClockSourceConfig.ClockSource = TIM_CLOCKSOURCE_INTERNAL;
  if (HAL_TIM_ConfigClockSource(&htim5, &sClockSourceConfig) != HAL_OK)
  {
    Error_Handler();
  }
  if (HAL_TIM_PWM_Init(&htim5) != HAL_OK)
  {
    Error_Handler();
  }
  sMasterConfig.MasterOutputTrigger = TIM_TRGO_RESET;
  sMasterConfig.MasterSlaveMode = TIM_MASTERSLAVEMODE_DISABLE;
  if (HAL_TIMEx_MasterConfigSynchronization(&htim5, &sMasterConfig) != HAL_OK)
  {
    Error_Handler();
  }
  sConfigOC.OCMode = TIM_OCMODE_PWM1;
  sConfigOC.Pulse = 200;
  sConfigOC.OCPolarity = TIM_OCPOLARITY_HIGH;
  sConfigOC.OCFastMode = TIM_OCFAST_DISABLE;
  if (HAL_TIM_PWM_ConfigChannel(&htim5, &sConfigOC, TIM_CHANNEL_2) != HAL_OK)
  {
    Error_Handler();
  }
  sConfigOC.Pulse = 400;
  if (HAL_TIM_PWM_ConfigChannel(&htim5, &sConfigOC, TIM_CHANNEL_3) != HAL_OK)
  {
    Error_Handler();
  }
  sConfigOC.Pulse = 600;
  if (HAL_TIM_PWM_ConfigChannel(&htim5, &sConfigOC, TIM_CHANNEL_4) != HAL_OK)
  {
    Error_Handler();
  }
  HAL_TIM_MspPostInit(&htim5);

}

static void MX_TIM6_Init(void)
{

  TIM_MasterConfigTypeDef sMasterConfig = {0};

  htim6.Instance = TIM6;
  htim6.Init.Prescaler = 170;
  htim6.Init.CounterMode = TIM_COUNTERMODE_UP;
  htim6.Init.Period = 49999;
  htim6.Init.AutoReloadPreload = TIM_AUTORELOAD_PRELOAD_ENABLE;
  if (HAL_TIM_Base_Init(&htim6) != HAL_OK)
  {
    Error_Handler();
  }
  sMasterConfig.MasterOutputTrigger = TIM_TRGO_RESET;
  sMasterConfig.MasterSlaveMode = TIM_MASTERSLAVEMODE_DISABLE;
  if (HAL_TIMEx_MasterConfigSynchronization(&htim6, &sMasterConfig) != HAL_OK)
  {
    Error_Handler();
  }

}

static void MX_TIM8_Init(void)
{

  LL_TIM_InitTypeDef TIM_InitStruct = {0};
  LL_TIM_OC_InitTypeDef TIM_OC_InitStruct = {0};
  LL_TIM_BDTR_InitTypeDef TIM_BDTRInitStruct = {0};

  LL_GPIO_InitTypeDef GPIO_InitStruct = {0};

  /* Peripheral clock enable */
  LL_APB2_GRP1_EnableClock(LL_APB2_GRP1_PERIPH_TIM8);

  TIM_InitStruct.Prescaler = 14399;
  TIM_InitStruct.CounterMode = LL_TIM_COUNTERMODE_UP;
  TIM_InitStruct.Autoreload = 99;
  TIM_InitStruct.ClockDivision = LL_TIM_CLOCKDIVISION_DIV1;
  TIM_InitStruct.RepetitionCounter = 0;
  LL_TIM_Init(TIM8, &TIM_InitStruct);
  LL_TIM_DisableARRPreload(TIM8);
  LL_TIM_SetClockSource(TIM8, LL_TIM_CLOCKSOURCE_INTERNAL);
  LL_TIM_OC_EnablePreload(TIM8, LL_TIM_CHANNEL_CH2);
  TIM_OC_InitStruct.OCMode = LL_TIM_OCMODE_PWM1;
  TIM_OC_InitStruct.OCState = LL_TIM_OCSTATE_DISABLE;
  TIM_OC_InitStruct.OCNState = LL_TIM_OCSTATE_DISABLE;
  TIM_OC_InitStruct.CompareValue = 2000;
  TIM_OC_InitStruct.OCPolarity = LL_TIM_OCPOLARITY_HIGH;
  TIM_OC_InitStruct.OCNPolarity = LL_TIM_OCPOLARITY_HIGH;
  TIM_OC_InitStruct.OCIdleState = LL_TIM_OCIDLESTATE_LOW;
  TIM_OC_InitStruct.OCNIdleState = LL_TIM_OCIDLESTATE_LOW;
  LL_TIM_OC_Init(TIM8, LL_TIM_CHANNEL_CH2, &TIM_OC_InitStruct);
  LL_TIM_OC_DisableFast(TIM8, LL_TIM_CHANNEL_CH2);
  LL_TIM_OC_EnablePreload(TIM8, LL_TIM_CHANNEL_CH3);
  TIM_OC_InitStruct.CompareValue = 4000;
  LL_TIM_OC_Init(TIM8, LL_TIM_CHANNEL_CH3, &TIM_OC_InitStruct);
  LL_TIM_OC_DisableFast(TIM8, LL_TIM_CHANNEL_CH3);
  LL_TIM_OC_EnablePreload(TIM8, LL_TIM_CHANNEL_CH4);
  TIM_OC_InitStruct.CompareValue = 8000;
  LL_TIM_OC_Init(TIM8, LL_TIM_CHANNEL_CH4, &TIM_OC_InitStruct);
  LL_TIM_OC_DisableFast(TIM8, LL_TIM_CHANNEL_CH4);
  LL_TIM_SetTriggerOutput(TIM8, LL_TIM_TRGO_RESET);
  LL_TIM_SetTriggerOutput2(TIM8, LL_TIM_TRGO2_RESET);
  LL_TIM_DisableMasterSlaveMode(TIM8);
  TIM_BDTRInitStruct.OSSRState = LL_TIM_OSSR_DISABLE;
  TIM_BDTRInitStruct.OSSIState = LL_TIM_OSSI_DISABLE;
  TIM_BDTRInitStruct.LockLevel = LL_TIM_LOCKLEVEL_OFF;
  TIM_BDTRInitStruct.DeadTime = 0;
  TIM_BDTRInitStruct.BreakState = LL_TIM_BREAK_DISABLE;
  TIM_BDTRInitStruct.BreakPolarity = LL_TIM_BREAK_POLARITY_HIGH;
  TIM_BDTRInitStruct.BreakFilter = LL_TIM_BREAK_FILTER_FDIV1;
  TIM_BDTRInitStruct.BreakAFMode = LL_TIM_BREAK_AFMODE_INPUT;
  TIM_BDTRInitStruct.Break2State = LL_TIM_BREAK2_DISABLE;
  TIM_BDTRInitStruct.Break2Polarity = LL_TIM_BREAK2_POLARITY_HIGH;
  TIM_BDTRInitStruct.Break2Filter = LL_TIM_BREAK2_FILTER_FDIV1;
  TIM_BDTRInitStruct.Break2AFMode = LL_TIM_BREAK_AFMODE_INPUT;
  TIM_BDTRInitStruct.AutomaticOutput = LL_TIM_AUTOMATICOUTPUT_DISABLE;
  LL_TIM_BDTR_Init(TIM8, &TIM_BDTRInitStruct);
  LL_AHB2_GRP1_EnableClock(LL_AHB2_GRP1_PERIPH_GPIOC);
  /**TIM8 GPIO Configuration
  PC7   ------> TIM8_CH2
  PC8   ------> TIM8_CH3
  PC9   ------> TIM8_CH4
  */
  GPIO_InitStruct.Pin = PWM11_Pin;
  GPIO_InitStruct.Mode = LL_GPIO_MODE_ALTERNATE;
  GPIO_InitStruct.Speed = LL_GPIO_SPEED_FREQ_LOW;
  GPIO_InitStruct.OutputType = LL_GPIO_OUTPUT_PUSHPULL;
  GPIO_InitStruct.Pull = LL_GPIO_PULL_NO;
  GPIO_InitStruct.Alternate = LL_GPIO_AF_4;
  LL_GPIO_Init(PWM11_GPIO_Port, &GPIO_InitStruct);

  GPIO_InitStruct.Pin = PWM12_Pin;
  GPIO_InitStruct.Mode = LL_GPIO_MODE_ALTERNATE;
  GPIO_InitStruct.Speed = LL_GPIO_SPEED_FREQ_LOW;
  GPIO_InitStruct.OutputType = LL_GPIO_OUTPUT_PUSHPULL;
  GPIO_InitStruct.Pull = LL_GPIO_PULL_NO;
  GPIO_InitStruct.Alternate = LL_GPIO_AF_4;
  LL_GPIO_Init(PWM12_GPIO_Port, &GPIO_InitStruct);

  GPIO_InitStruct.Pin = PWM13_Pin;
  GPIO_InitStruct.Mode = LL_GPIO_MODE_ALTERNATE;
  GPIO_InitStruct.Speed = LL_GPIO_SPEED_FREQ_LOW;
  GPIO_InitStruct.OutputType = LL_GPIO_OUTPUT_PUSHPULL;
  GPIO_InitStruct.Pull = LL_GPIO_PULL_NO;
  GPIO_InitStruct.Alternate = LL_GPIO_AF_4;
  LL_GPIO_Init(PWM13_GPIO_Port, &GPIO_InitStruct);

}

static void MX_TIM15_Init(void)
{

  TIM_ClockConfigTypeDef sClockSourceConfig = {0};
  TIM_MasterConfigTypeDef sMasterConfig = {0};
  TIM_OC_InitTypeDef sConfigOC = {0};
  TIM_BreakDeadTimeConfigTypeDef sBreakDeadTimeConfig = {0};

  htim15.Instance = TIM15;
  htim15.Init.Prescaler = 0;
  htim15.Init.CounterMode = TIM_COUNTERMODE_UP;
  htim15.Init.Period = 32768;
  htim15.Init.ClockDivision = TIM_CLOCKDIVISION_DIV1;
  htim15.Init.RepetitionCounter = 0;
  htim15.Init.AutoReloadPreload = TIM_AUTORELOAD_PRELOAD_DISABLE;
  if (HAL_TIM_Base_Init(&htim15) != HAL_OK)
  {
    Error_Handler();
  }
  sClockSourceConfig.ClockSource = TIM_CLOCKSOURCE_INTERNAL;
  if (HAL_TIM_ConfigClockSource(&htim15, &sClockSourceConfig) != HAL_OK)
  {
    Error_Handler();
  }
  if (HAL_TIM_PWM_Init(&htim15) != HAL_OK)
  {
    Error_Handler();
  }
  sMasterConfig.MasterOutputTrigger = TIM_TRGO_RESET;
  sMasterConfig.MasterSlaveMode = TIM_MASTERSLAVEMODE_DISABLE;
  if (HAL_TIMEx_MasterConfigSynchronization(&htim15, &sMasterConfig) != HAL_OK)
  {
    Error_Handler();
  }
  sConfigOC.OCMode = TIM_OCMODE_PWM1;
  sConfigOC.Pulse = 16000;
  sConfigOC.OCPolarity = TIM_OCPOLARITY_HIGH;
  sConfigOC.OCNPolarity = TIM_OCNPOLARITY_HIGH;
  sConfigOC.OCFastMode = TIM_OCFAST_DISABLE;
  sConfigOC.OCIdleState = TIM_OCIDLESTATE_RESET;
  sConfigOC.OCNIdleState = TIM_OCNIDLESTATE_RESET;
  if (HAL_TIM_PWM_ConfigChannel(&htim15, &sConfigOC, TIM_CHANNEL_2) != HAL_OK)
  {
    Error_Handler();
  }
  sBreakDeadTimeConfig.OffStateRunMode = TIM_OSSR_DISABLE;
  sBreakDeadTimeConfig.OffStateIDLEMode = TIM_OSSI_DISABLE;
  sBreakDeadTimeConfig.LockLevel = TIM_LOCKLEVEL_OFF;
  sBreakDeadTimeConfig.DeadTime = 0;
  sBreakDeadTimeConfig.BreakState = TIM_BREAK_DISABLE;
  sBreakDeadTimeConfig.BreakPolarity = TIM_BREAKPOLARITY_HIGH;
  sBreakDeadTimeConfig.BreakFilter = 0;
  sBreakDeadTimeConfig.AutomaticOutput = TIM_AUTOMATICOUTPUT_DISABLE;
  if (HAL_TIMEx_ConfigBreakDeadTime(&htim15, &sBreakDeadTimeConfig) != HAL_OK)
  {
    Error_Handler();
  }
  HAL_TIM_MspPostInit(&htim15);

}

static void MX_TIM20_Init(void)
{

  TIM_ClockConfigTypeDef sClockSourceConfig = {0};
  TIM_MasterConfigTypeDef sMasterConfig = {0};
  TIM_OC_InitTypeDef sConfigOC = {0};
  TIM_BreakDeadTimeConfigTypeDef sBreakDeadTimeConfig = {0};

  htim20.Instance = TIM20;
  htim20.Init.Prescaler = 0;
  htim20.Init.CounterMode = TIM_COUNTERMODE_UP;
  htim20.Init.Period = 16000;
  htim20.Init.ClockDivision = TIM_CLOCKDIVISION_DIV1;
  htim20.Init.RepetitionCounter = 0;
  htim20.Init.AutoReloadPreload = TIM_AUTORELOAD_PRELOAD_DISABLE;
  if (HAL_TIM_Base_Init(&htim20) != HAL_OK)
  {
    Error_Handler();
  }
  sClockSourceConfig.ClockSource = TIM_CLOCKSOURCE_INTERNAL;
  if (HAL_TIM_ConfigClockSource(&htim20, &sClockSourceConfig) != HAL_OK)
  {
    Error_Handler();
  }
  if (HAL_TIM_PWM_Init(&htim20) != HAL_OK)
  {
    Error_Handler();
  }
  sMasterConfig.MasterOutputTrigger = TIM_TRGO_RESET;
  sMasterConfig.MasterOutputTrigger2 = TIM_TRGO2_RESET;
  sMasterConfig.MasterSlaveMode = TIM_MASTERSLAVEMODE_DISABLE;
  if (HAL_TIMEx_MasterConfigSynchronization(&htim20, &sMasterConfig) != HAL_OK)
  {
    Error_Handler();
  }
  sConfigOC.OCMode = TIM_OCMODE_PWM1;
  sConfigOC.Pulse = 8000;
  sConfigOC.OCPolarity = TIM_OCPOLARITY_HIGH;
  sConfigOC.OCNPolarity = TIM_OCNPOLARITY_HIGH;
  sConfigOC.OCFastMode = TIM_OCFAST_DISABLE;
  sConfigOC.OCIdleState = TIM_OCIDLESTATE_RESET;
  sConfigOC.OCNIdleState = TIM_OCNIDLESTATE_RESET;
  if (HAL_TIM_PWM_ConfigChannel(&htim20, &sConfigOC, TIM_CHANNEL_1) != HAL_OK)
  {
    Error_Handler();
  }
  sConfigOC.Pulse = 10000;
  if (HAL_TIM_PWM_ConfigChannel(&htim20, &sConfigOC, TIM_CHANNEL_2) != HAL_OK)
  {
    Error_Handler();
  }
  sConfigOC.Pulse = 12000;
  if (HAL_TIM_PWM_ConfigChannel(&htim20, &sConfigOC, TIM_CHANNEL_3) != HAL_OK)
  {
    Error_Handler();
  }
  sConfigOC.Pulse = 15000;
  if (HAL_TIM_PWM_ConfigChannel(&htim20, &sConfigOC, TIM_CHANNEL_4) != HAL_OK)
  {
    Error_Handler();
  }
  sBreakDeadTimeConfig.OffStateRunMode = TIM_OSSR_DISABLE;
  sBreakDeadTimeConfig.OffStateIDLEMode = TIM_OSSI_DISABLE;
  sBreakDeadTimeConfig.LockLevel = TIM_LOCKLEVEL_OFF;
  sBreakDeadTimeConfig.DeadTime = 0;
  sBreakDeadTimeConfig.BreakState = TIM_BREAK_DISABLE;
  sBreakDeadTimeConfig.BreakPolarity = TIM_BREAKPOLARITY_HIGH;
  sBreakDeadTimeConfig.BreakFilter = 0;
  sBreakDeadTimeConfig.BreakAFMode = TIM_BREAK_AFMODE_INPUT;
  sBreakDeadTimeConfig.Break2State = TIM_BREAK2_DISABLE;
  sBreakDeadTimeConfig.Break2Polarity = TIM_BREAK2POLARITY_HIGH;
  sBreakDeadTimeConfig.Break2Filter = 0;
  sBreakDeadTimeConfig.Break2AFMode = TIM_BREAK_AFMODE_INPUT;
  sBreakDeadTimeConfig.AutomaticOutput = TIM_AUTOMATICOUTPUT_DISABLE;
  if (HAL_TIMEx_ConfigBreakDeadTime(&htim20, &sBreakDeadTimeConfig) != HAL_OK)
  {
    Error_Handler();
  }
  HAL_TIM_MspPostInit(&htim20);

}

static void MX_UART4_Init(void)
{

  huart4.Instance = UART4;
  huart4.Init.BaudRate = 115200;
  huart4.Init.WordLength = UART_WORDLENGTH_8B;
  huart4.Init.StopBits = UART_STOPBITS_1;
  huart4.Init.Parity = UART_PARITY_NONE;
  huart4.Init.Mode = UART_MODE_TX_RX;
  huart4.Init.HwFlowCtl = UART_HWCONTROL_NONE;
  huart4.Init.OverSampling = UART_OVERSAMPLING_16;
  huart4.Init.OneBitSampling = UART_ONE_BIT_SAMPLE_DISABLE;
  huart4.Init.ClockPrescaler = UART_PRESCALER_DIV1;
  huart4.AdvancedInit.AdvFeatureInit = UART_ADVFEATURE_NO_INIT;
  if (HAL_UART_Init(&huart4) != HAL_OK)
  {
    Error_Handler();
  }
  if (HAL_UARTEx_SetTxFifoThreshold(&huart4, UART_TXFIFO_THRESHOLD_1_8) != HAL_OK)
  {
    Error_Handler();
  }
  if (HAL_UARTEx_SetRxFifoThreshold(&huart4, UART_RXFIFO_THRESHOLD_1_8) != HAL_OK)
  {
    Error_Handler();
  }
  if (HAL_UARTEx_DisableFifoMode(&huart4) != HAL_OK)
  {
    Error_Handler();
  }

}

static void MX_UART5_Init(void)
{

  huart5.Instance = UART5;
  huart5.Init.BaudRate = 115200;
  huart5.Init.WordLength = UART_WORDLENGTH_8B;
  huart5.Init.StopBits = UART_STOPBITS_1;
  huart5.Init.Parity = UART_PARITY_NONE;
  huart5.Init.Mode = UART_MODE_TX_RX;
  huart5.Init.HwFlowCtl = UART_HWCONTROL_NONE;
  huart5.Init.OverSampling = UART_OVERSAMPLING_16;
  huart5.Init.OneBitSampling = UART_ONE_BIT_SAMPLE_DISABLE;
  huart5.Init.ClockPrescaler = UART_PRESCALER_DIV1;
  huart5.AdvancedInit.AdvFeatureInit = UART_ADVFEATURE_NO_INIT;
  if (HAL_UART_Init(&huart5) != HAL_OK)
  {
    Error_Handler();
  }
  if (HAL_UARTEx_SetTxFifoThreshold(&huart5, UART_TXFIFO_THRESHOLD_1_8) != HAL_OK)
  {
    Error_Handler();
  }
  if (HAL_UARTEx_SetRxFifoThreshold(&huart5, UART_RXFIFO_THRESHOLD_1_8) != HAL_OK)
  {
    Error_Handler();
  }
  if (HAL_UARTEx_DisableFifoMode(&huart5) != HAL_OK)
  {
    Error_Handler();
  }

}

static void MX_USART1_UART_Init(void)
{

  huart1.Instance = USART1;
  huart1.Init.BaudRate = 115200;
  huart1.Init.WordLength = UART_WORDLENGTH_8B;
  huart1.Init.StopBits = UART_STOPBITS_1;
  huart1.Init.Parity = UART_PARITY_NONE;
  huart1.Init.Mode = UART_MODE_TX_RX;
  huart1.Init.HwFlowCtl = UART_HWCONTROL_NONE;
  huart1.Init.OverSampling = UART_OVERSAMPLING_16;
  huart1.Init.OneBitSampling = UART_ONE_BIT_SAMPLE_DISABLE;
  huart1.Init.ClockPrescaler = UART_PRESCALER_DIV1;
  huart1.AdvancedInit.AdvFeatureInit = UART_ADVFEATURE_NO_INIT;
  if (HAL_UART_Init(&huart1) != HAL_OK)
  {
    Error_Handler();
  }
  if (HAL_UARTEx_SetTxFifoThreshold(&huart1, UART_TXFIFO_THRESHOLD_1_8) != HAL_OK)
  {
    Error_Handler();
  }
  if (HAL_UARTEx_SetRxFifoThreshold(&huart1, UART_RXFIFO_THRESHOLD_1_8) != HAL_OK)
  {
    Error_Handler();
  }
  if (HAL_UARTEx_DisableFifoMode(&huart1) != HAL_OK)
  {
    Error_Handler();
  }

}

static void MX_USART2_UART_Init(void)
{

  huart2.Instance = USART2;
  huart2.Init.BaudRate = 115200;
  huart2.Init.WordLength = UART_WORDLENGTH_8B;
  huart2.Init.StopBits = UART_STOPBITS_1;
  huart2.Init.Parity = UART_PARITY_NONE;
  huart2.Init.Mode = UART_MODE_TX_RX;
  huart2.Init.HwFlowCtl = UART_HWCONTROL_NONE;
  huart2.Init.OverSampling = UART_OVERSAMPLING_16;
  huart2.Init.OneBitSampling = UART_ONE_BIT_SAMPLE_DISABLE;
  huart2.Init.ClockPrescaler = UART_PRESCALER_DIV1;
  huart2.AdvancedInit.AdvFeatureInit = UART_ADVFEATURE_NO_INIT;
  if (HAL_UART_Init(&huart2) != HAL_OK)
  {
    Error_Handler();
  }
  if (HAL_UARTEx_SetTxFifoThreshold(&huart2, UART_TXFIFO_THRESHOLD_1_8) != HAL_OK)
  {
    Error_Handler();
  }
  if (HAL_UARTEx_SetRxFifoThreshold(&huart2, UART_RXFIFO_THRESHOLD_1_8) != HAL_OK)
  {
    Error_Handler();
  }
  if (HAL_UARTEx_DisableFifoMode(&huart2) != HAL_OK)
  {
    Error_Handler();
  }

}

static void MX_USART3_UART_Init(void)
{

  LL_USART_InitTypeDef USART_InitStruct = {0};

  LL_GPIO_InitTypeDef GPIO_InitStruct = {0};
  RCC_PeriphCLKInitTypeDef PeriphClkInit = {0};

  /** Initializes the peripherals clocks
  */
  PeriphClkInit.PeriphClockSelection = RCC_PERIPHCLK_USART3;
  PeriphClkInit.Usart3ClockSelection = RCC_USART3CLKSOURCE_PCLK1;
  if (HAL_RCCEx_PeriphCLKConfig(&PeriphClkInit) != HAL_OK)
  {
    Error_Handler();
  }

  /* Peripheral clock enable */
  LL_APB1_GRP1_EnableClock(LL_APB1_GRP1_PERIPH_USART3);

  LL_AHB2_GRP1_EnableClock(LL_AHB2_GRP1_PERIPH_GPIOB);
  /**USART3 GPIO Configuration
  PB8-BOOT0   ------> USART3_RX
  PB9   ------> USART3_TX
  */
  GPIO_InitStruct.Pin = LL_GPIO_PIN_8;
  GPIO_InitStruct.Mode = LL_GPIO_MODE_ALTERNATE;
  GPIO_InitStruct.Speed = LL_GPIO_SPEED_FREQ_LOW;
  GPIO_InitStruct.OutputType = LL_GPIO_OUTPUT_PUSHPULL;
  GPIO_InitStruct.Pull = LL_GPIO_PULL_NO;
  GPIO_InitStruct.Alternate = LL_GPIO_AF_7;
  LL_GPIO_Init(GPIOB, &GPIO_InitStruct);

  GPIO_InitStruct.Pin = LL_GPIO_PIN_9;
  GPIO_InitStruct.Mode = LL_GPIO_MODE_ALTERNATE;
  GPIO_InitStruct.Speed = LL_GPIO_SPEED_FREQ_LOW;
  GPIO_InitStruct.OutputType = LL_GPIO_OUTPUT_PUSHPULL;
  GPIO_InitStruct.Pull = LL_GPIO_PULL_NO;
  GPIO_InitStruct.Alternate = LL_GPIO_AF_7;
  LL_GPIO_Init(GPIOB, &GPIO_InitStruct);

  /* USART3 interrupt Init */
  NVIC_SetPriority(USART3_IRQn, NVIC_EncodePriority(NVIC_GetPriorityGrouping(),0, 0));
  NVIC_EnableIRQ(USART3_IRQn);

  USART_InitStruct.PrescalerValue = LL_USART_PRESCALER_DIV1;
  USART_InitStruct.BaudRate = 115200;
  USART_InitStruct.DataWidth = LL_USART_DATAWIDTH_8B;
  USART_InitStruct.StopBits = LL_USART_STOPBITS_1;
  USART_InitStruct.Parity = LL_USART_PARITY_NONE;
  USART_InitStruct.TransferDirection = LL_USART_DIRECTION_TX_RX;
  USART_InitStruct.HardwareFlowControl = LL_USART_HWCONTROL_NONE;
  USART_InitStruct.OverSampling = LL_USART_OVERSAMPLING_16;
  LL_USART_Init(USART3, &USART_InitStruct);
  LL_USART_SetTXFIFOThreshold(USART3, LL_USART_FIFOTHRESHOLD_1_8);
  LL_USART_SetRXFIFOThreshold(USART3, LL_USART_FIFOTHRESHOLD_1_8);
  LL_USART_DisableFIFO(USART3);
  LL_USART_ConfigAsyncMode(USART3);

  LL_USART_Enable(USART3);

  /* Polling USART3 initialisation */
  while((!(LL_USART_IsActiveFlag_TEACK(USART3))) || (!(LL_USART_IsActiveFlag_REACK(USART3))))
  {
  }

}

static void MX_DMA_Init(void)
{

  /* DMA controller clock enable */
  __HAL_RCC_DMAMUX1_CLK_ENABLE();
  __HAL_RCC_DMA1_CLK_ENABLE();

  /* DMA interrupt init */
  /* DMA1_Channel1_IRQn interrupt configuration */
  HAL_NVIC_SetPriority(DMA1_Channel1_IRQn, 0, 0);
  HAL_NVIC_EnableIRQ(DMA1_Channel1_IRQn);
  /* DMA1_Channel2_IRQn interrupt configuration */
  HAL_NVIC_SetPriority(DMA1_Channel2_IRQn, 0, 0);
  HAL_NVIC_EnableIRQ(DMA1_Channel2_IRQn);
  /* DMA1_Channel3_IRQn interrupt configuration */
  HAL_NVIC_SetPriority(DMA1_Channel3_IRQn, 0, 0);
  HAL_NVIC_EnableIRQ(DMA1_Channel3_IRQn);
  /* DMA1_Channel4_IRQn interrupt configuration */
  HAL_NVIC_SetPriority(DMA1_Channel4_IRQn, 0, 0);
  HAL_NVIC_EnableIRQ(DMA1_Channel4_IRQn);
  /* DMA1_Channel5_IRQn interrupt configuration */
  HAL_NVIC_SetPriority(DMA1_Channel5_IRQn, 0, 0);
  HAL_NVIC_EnableIRQ(DMA1_Channel5_IRQn);

}

/* FMC initialization function */
static void MX_FMC_Init(void)
{

  FMC_NORSRAM_TimingTypeDef Timing = {0};

  /** Perform the SRAM1 memory initialization sequence
  */
  hsram1.Instance = FMC_NORSRAM_DEVICE;
  hsram1.Extended = FMC_NORSRAM_EXTENDED_DEVICE;
  /* hsram1.Init */
  hsram1.Init.NSBank = FMC_NORSRAM_BANK1;
  hsram1.Init.DataAddressMux = FMC_DATA_ADDRESS_MUX_DISABLE;
  hsram1.Init.MemoryType = FMC_MEMORY_TYPE_SRAM;
  hsram1.Init.MemoryDataWidth = FMC_NORSRAM_MEM_BUS_WIDTH_16;
  hsram1.Init.BurstAccessMode = FMC_BURST_ACCESS_MODE_DISABLE;
  hsram1.Init.WaitSignalPolarity = FMC_WAIT_SIGNAL_POLARITY_LOW;
  hsram1.Init.WaitSignalActive = FMC_WAIT_TIMING_BEFORE_WS;
  hsram1.Init.WriteOperation = FMC_WRITE_OPERATION_ENABLE;
  hsram1.Init.WaitSignal = FMC_WAIT_SIGNAL_DISABLE;
  hsram1.Init.ExtendedMode = FMC_EXTENDED_MODE_DISABLE;
  hsram1.Init.AsynchronousWait = FMC_ASYNCHRONOUS_WAIT_DISABLE;
  hsram1.Init.WriteBurst = FMC_WRITE_BURST_DISABLE;
  hsram1.Init.ContinuousClock = FMC_CONTINUOUS_CLOCK_SYNC_ONLY;
  hsram1.Init.WriteFifo = FMC_WRITE_FIFO_ENABLE;
  hsram1.Init.NBLSetupTime = 0;
  hsram1.Init.PageSize = FMC_PAGE_SIZE_NONE;
  hsram1.Init.MaxChipSelectPulse = DISABLE;
  /* Timing */
  Timing.AddressSetupTime = 3;
  Timing.AddressHoldTime = 15;
  Timing.DataSetupTime = 3;
  Timing.DataHoldTime = 3;
  Timing.BusTurnAroundDuration = 3;
  Timing.CLKDivision = 16;
  Timing.DataLatency = 17;
  Timing.AccessMode = FMC_ACCESS_MODE_A;
  /* ExtTiming */

  if (HAL_SRAM_Init(&hsram1, &Timing, NULL) != HAL_OK)
  {
    Error_Handler( );
  }

}

static void MX_GPIO_Init(void)
{
  LL_EXTI_InitTypeDef EXTI_InitStruct = {0};
  LL_GPIO_InitTypeDef GPIO_InitStruct = {0};

  /* GPIO Ports Clock Enable */
  LL_AHB2_GRP1_EnableClock(LL_AHB2_GRP1_PERIPH_GPIOE);
  LL_AHB2_GRP1_EnableClock(LL_AHB2_GRP1_PERIPH_GPIOC);
  LL_AHB2_GRP1_EnableClock(LL_AHB2_GRP1_PERIPH_GPIOF);
  LL_AHB2_GRP1_EnableClock(LL_AHB2_GRP1_PERIPH_GPIOA);
  LL_AHB2_GRP1_EnableClock(LL_AHB2_GRP1_PERIPH_GPIOB);
  LL_AHB2_GRP1_EnableClock(LL_AHB2_GRP1_PERIPH_GPIOD);
  LL_AHB2_GRP1_EnableClock(LL_AHB2_GRP1_PERIPH_GPIOG);

  /**/
  LL_GPIO_ResetOutputPin(LED1_GPIO_Port, LED1_Pin);

  /**/
  LL_GPIO_ResetOutputPin(LED2_GPIO_Port, LED2_Pin);

  /**/
  LL_GPIO_ResetOutputPin(LED3_GPIO_Port, LED3_Pin);

  /**/
  LL_GPIO_ResetOutputPin(LED4_GPIO_Port, LED4_Pin);

  /**/
  LL_GPIO_ResetOutputPin(LED5_GPIO_Port, LED5_Pin);

  /**/
  LL_GPIO_ResetOutputPin(LED6_GPIO_Port, LED6_Pin);

  /**/
  LL_GPIO_ResetOutputPin(LED7_GPIO_Port, LED7_Pin);

  /**/
  LL_GPIO_ResetOutputPin(LED0_GPIO_Port, LED0_Pin);

  /**/
  LL_GPIO_ResetOutputPin(GPIOA, LL_GPIO_PIN_4);

  /**/
  LL_GPIO_ResetOutputPin(GPIOA, LL_GPIO_PIN_6);

  /**/
  LL_GPIO_ResetOutputPin(ARDUINO_CS_GPIO_Port, ARDUINO_CS_Pin);

  /**/
  LL_GPIO_ResetOutputPin(CAN_STBY_GPIO_Port, CAN_STBY_Pin);

  /**/
  LL_GPIO_ResetOutputPin(LCD_RST_GPIO_Port, LCD_RST_Pin);

  /**/
  LL_GPIO_ResetOutputPin(LIN_SLP_GPIO_Port, LIN_SLP_Pin);

  /**/
  LL_GPIO_ResetOutputPin(FLASH_CS_GPIO_Port, FLASH_CS_Pin);

  /**/
  LL_GPIO_SetOutputPin(TOUCH_CS_GPIO_Port, TOUCH_CS_Pin);

  /**/
  GPIO_InitStruct.Pin = JOY_BTN_Pin;
  GPIO_InitStruct.Mode = LL_GPIO_MODE_INPUT;
  GPIO_InitStruct.Pull = LL_GPIO_PULL_UP;
  LL_GPIO_Init(JOY_BTN_GPIO_Port, &GPIO_InitStruct);

  /**/
  GPIO_InitStruct.Pin = BTN_OK_Pin;
  GPIO_InitStruct.Mode = LL_GPIO_MODE_INPUT;
  GPIO_InitStruct.Pull = LL_GPIO_PULL_UP;
  LL_GPIO_Init(BTN_OK_GPIO_Port, &GPIO_InitStruct);

  /**/
  GPIO_InitStruct.Pin = LED1_Pin;
  GPIO_InitStruct.Mode = LL_GPIO_MODE_OUTPUT;
  GPIO_InitStruct.Speed = LL_GPIO_SPEED_FREQ_LOW;
  GPIO_InitStruct.OutputType = LL_GPIO_OUTPUT_PUSHPULL;
  GPIO_InitStruct.Pull = LL_GPIO_PULL_NO;
  LL_GPIO_Init(LED1_GPIO_Port, &GPIO_InitStruct);

  /**/
  GPIO_InitStruct.Pin = LED2_Pin;
  GPIO_InitStruct.Mode = LL_GPIO_MODE_OUTPUT;
  GPIO_InitStruct.Speed = LL_GPIO_SPEED_FREQ_LOW;
  GPIO_InitStruct.OutputType = LL_GPIO_OUTPUT_PUSHPULL;
  GPIO_InitStruct.Pull = LL_GPIO_PULL_NO;
  LL_GPIO_Init(LED2_GPIO_Port, &GPIO_InitStruct);

  /**/
  GPIO_InitStruct.Pin = LED3_Pin;
  GPIO_InitStruct.Mode = LL_GPIO_MODE_OUTPUT;
  GPIO_InitStruct.Speed = LL_GPIO_SPEED_FREQ_LOW;
  GPIO_InitStruct.OutputType = LL_GPIO_OUTPUT_PUSHPULL;
  GPIO_InitStruct.Pull = LL_GPIO_PULL_NO;
  LL_GPIO_Init(LED3_GPIO_Port, &GPIO_InitStruct);

  /**/
  GPIO_InitStruct.Pin = AD5_Pin;
  GPIO_InitStruct.Mode = LL_GPIO_MODE_ANALOG;
  GPIO_InitStruct.Pull = LL_GPIO_PULL_NO;
  LL_GPIO_Init(AD5_GPIO_Port, &GPIO_InitStruct);

  /**/
  GPIO_InitStruct.Pin = LED4_Pin;
  GPIO_InitStruct.Mode = LL_GPIO_MODE_OUTPUT;
  GPIO_InitStruct.Speed = LL_GPIO_SPEED_FREQ_LOW;
  GPIO_InitStruct.OutputType = LL_GPIO_OUTPUT_PUSHPULL;
  GPIO_InitStruct.Pull = LL_GPIO_PULL_NO;
  LL_GPIO_Init(LED4_GPIO_Port, &GPIO_InitStruct);

  /**/
  GPIO_InitStruct.Pin = LED5_Pin;
  GPIO_InitStruct.Mode = LL_GPIO_MODE_OUTPUT;
  GPIO_InitStruct.Speed = LL_GPIO_SPEED_FREQ_LOW;
  GPIO_InitStruct.OutputType = LL_GPIO_OUTPUT_PUSHPULL;
  GPIO_InitStruct.Pull = LL_GPIO_PULL_NO;
  LL_GPIO_Init(LED5_GPIO_Port, &GPIO_InitStruct);

  /**/
  GPIO_InitStruct.Pin = LED6_Pin;
  GPIO_InitStruct.Mode = LL_GPIO_MODE_OUTPUT;
  GPIO_InitStruct.Speed = LL_GPIO_SPEED_FREQ_LOW;
  GPIO_InitStruct.OutputType = LL_GPIO_OUTPUT_PUSHPULL;
  GPIO_InitStruct.Pull = LL_GPIO_PULL_NO;
  LL_GPIO_Init(LED6_GPIO_Port, &GPIO_InitStruct);

  /**/
  GPIO_InitStruct.Pin = LED7_Pin;
  GPIO_InitStruct.Mode = LL_GPIO_MODE_OUTPUT;
  GPIO_InitStruct.Speed = LL_GPIO_SPEED_FREQ_LOW;
  GPIO_InitStruct.OutputType = LL_GPIO_OUTPUT_PUSHPULL;
  GPIO_InitStruct.Pull = LL_GPIO_PULL_NO;
  LL_GPIO_Init(LED7_GPIO_Port, &GPIO_InitStruct);

  /**/
  GPIO_InitStruct.Pin = LED0_Pin;
  GPIO_InitStruct.Mode = LL_GPIO_MODE_OUTPUT;
  GPIO_InitStruct.Speed = LL_GPIO_SPEED_FREQ_VERY_HIGH;
  GPIO_InitStruct.OutputType = LL_GPIO_OUTPUT_PUSHPULL;
  GPIO_InitStruct.Pull = LL_GPIO_PULL_NO;
  LL_GPIO_Init(LED0_GPIO_Port, &GPIO_InitStruct);

  /**/
  GPIO_InitStruct.Pin = AD2_Pin;
  GPIO_InitStruct.Mode = LL_GPIO_MODE_ANALOG;
  GPIO_InitStruct.Pull = LL_GPIO_PULL_NO;
  LL_GPIO_Init(AD2_GPIO_Port, &GPIO_InitStruct);

  /**/
  GPIO_InitStruct.Pin = AD3_Pin;
  GPIO_InitStruct.Mode = LL_GPIO_MODE_ANALOG;
  GPIO_InitStruct.Pull = LL_GPIO_PULL_NO;
  LL_GPIO_Init(AD3_GPIO_Port, &GPIO_InitStruct);

  /**/
  GPIO_InitStruct.Pin = LL_GPIO_PIN_4;
  GPIO_InitStruct.Mode = LL_GPIO_MODE_OUTPUT;
  GPIO_InitStruct.Speed = LL_GPIO_SPEED_FREQ_LOW;
  GPIO_InitStruct.OutputType = LL_GPIO_OUTPUT_PUSHPULL;
  GPIO_InitStruct.Pull = LL_GPIO_PULL_NO;
  LL_GPIO_Init(GPIOA, &GPIO_InitStruct);

  /**/
  GPIO_InitStruct.Pin = AD8_Pin;
  GPIO_InitStruct.Mode = LL_GPIO_MODE_ANALOG;
  GPIO_InitStruct.Pull = LL_GPIO_PULL_NO;
  LL_GPIO_Init(AD8_GPIO_Port, &GPIO_InitStruct);

  /**/
  GPIO_InitStruct.Pin = LL_GPIO_PIN_6;
  GPIO_InitStruct.Mode = LL_GPIO_MODE_OUTPUT;
  GPIO_InitStruct.Speed = LL_GPIO_SPEED_FREQ_LOW;
  GPIO_InitStruct.OutputType = LL_GPIO_OUTPUT_PUSHPULL;
  GPIO_InitStruct.Pull = LL_GPIO_PULL_NO;
  LL_GPIO_Init(GPIOA, &GPIO_InitStruct);

  /**/
  GPIO_InitStruct.Pin = AD4_Pin;
  GPIO_InitStruct.Mode = LL_GPIO_MODE_ANALOG;
  GPIO_InitStruct.Pull = LL_GPIO_PULL_NO;
  LL_GPIO_Init(AD4_GPIO_Port, &GPIO_InitStruct);

  /**/
  GPIO_InitStruct.Pin = AD6_Pin;
  GPIO_InitStruct.Mode = LL_GPIO_MODE_ANALOG;
  GPIO_InitStruct.Pull = LL_GPIO_PULL_NO;
  LL_GPIO_Init(AD6_GPIO_Port, &GPIO_InitStruct);

  /**/
  GPIO_InitStruct.Pin = ARDUINO_CS_Pin;
  GPIO_InitStruct.Mode = LL_GPIO_MODE_OUTPUT;
  GPIO_InitStruct.Speed = LL_GPIO_SPEED_FREQ_LOW;
  GPIO_InitStruct.OutputType = LL_GPIO_OUTPUT_PUSHPULL;
  GPIO_InitStruct.Pull = LL_GPIO_PULL_NO;
  LL_GPIO_Init(ARDUINO_CS_GPIO_Port, &GPIO_InitStruct);

  /**/
  GPIO_InitStruct.Pin = AD9_Pin;
  GPIO_InitStruct.Mode = LL_GPIO_MODE_ANALOG;
  GPIO_InitStruct.Pull = LL_GPIO_PULL_NO;
  LL_GPIO_Init(AD9_GPIO_Port, &GPIO_InitStruct);

  /**/
  GPIO_InitStruct.Pin = AD10_Pin;
  GPIO_InitStruct.Mode = LL_GPIO_MODE_ANALOG;
  GPIO_InitStruct.Pull = LL_GPIO_PULL_NO;
  LL_GPIO_Init(AD10_GPIO_Port, &GPIO_InitStruct);

  /**/
  GPIO_InitStruct.Pin = AD11_Pin;
  GPIO_InitStruct.Mode = LL_GPIO_MODE_ANALOG;
  GPIO_InitStruct.Pull = LL_GPIO_PULL_NO;
  LL_GPIO_Init(AD11_GPIO_Port, &GPIO_InitStruct);

  /**/
  GPIO_InitStruct.Pin = BTN_UP_Pin;
  GPIO_InitStruct.Mode = LL_GPIO_MODE_INPUT;
  GPIO_InitStruct.Pull = LL_GPIO_PULL_UP;
  LL_GPIO_Init(BTN_UP_GPIO_Port, &GPIO_InitStruct);

  /**/
  GPIO_InitStruct.Pin = BTN_DOWN_Pin;
  GPIO_InitStruct.Mode = LL_GPIO_MODE_INPUT;
  GPIO_InitStruct.Pull = LL_GPIO_PULL_UP;
  LL_GPIO_Init(BTN_DOWN_GPIO_Port, &GPIO_InitStruct);

  /**/
  GPIO_InitStruct.Pin = BTN_LEFT_Pin;
  GPIO_InitStruct.Mode = LL_GPIO_MODE_INPUT;
  GPIO_InitStruct.Pull = LL_GPIO_PULL_UP;
  LL_GPIO_Init(BTN_LEFT_GPIO_Port, &GPIO_InitStruct);

  /**/
  GPIO_InitStruct.Pin = CAN_STBY_Pin;
  GPIO_InitStruct.Mode = LL_GPIO_MODE_OUTPUT;
  GPIO_InitStruct.Speed = LL_GPIO_SPEED_FREQ_LOW;
  GPIO_InitStruct.OutputType = LL_GPIO_OUTPUT_PUSHPULL;
  GPIO_InitStruct.Pull = LL_GPIO_PULL_NO;
  LL_GPIO_Init(CAN_STBY_GPIO_Port, &GPIO_InitStruct);

  /**/
  GPIO_InitStruct.Pin = BTN_RIGHT_Pin;
  GPIO_InitStruct.Mode = LL_GPIO_MODE_INPUT;
  GPIO_InitStruct.Pull = LL_GPIO_PULL_UP;
  LL_GPIO_Init(BTN_RIGHT_GPIO_Port, &GPIO_InitStruct);

  /**/
  GPIO_InitStruct.Pin = LCD_RST_Pin;
  GPIO_InitStruct.Mode = LL_GPIO_MODE_OUTPUT;
  GPIO_InitStruct.Speed = LL_GPIO_SPEED_FREQ_LOW;
  GPIO_InitStruct.OutputType = LL_GPIO_OUTPUT_PUSHPULL;
  GPIO_InitStruct.Pull = LL_GPIO_PULL_NO;
  LL_GPIO_Init(LCD_RST_GPIO_Port, &GPIO_InitStruct);

  /**/
  GPIO_InitStruct.Pin = LIN_SLP_Pin;
  GPIO_InitStruct.Mode = LL_GPIO_MODE_OUTPUT;
  GPIO_InitStruct.Speed = LL_GPIO_SPEED_FREQ_LOW;
  GPIO_InitStruct.OutputType = LL_GPIO_OUTPUT_PUSHPULL;
  GPIO_InitStruct.Pull = LL_GPIO_PULL_NO;
  LL_GPIO_Init(LIN_SLP_GPIO_Port, &GPIO_InitStruct);

  /**/
  GPIO_InitStruct.Pin = FLASH_CS_Pin;
  GPIO_InitStruct.Mode = LL_GPIO_MODE_OUTPUT;
  GPIO_InitStruct.Speed = LL_GPIO_SPEED_FREQ_LOW;
  GPIO_InitStruct.OutputType = LL_GPIO_OUTPUT_PUSHPULL;
  GPIO_InitStruct.Pull = LL_GPIO_PULL_NO;
  LL_GPIO_Init(FLASH_CS_GPIO_Port, &GPIO_InitStruct);

  /**/
  GPIO_InitStruct.Pin = TOUCH_CS_Pin;
  GPIO_InitStruct.Mode = LL_GPIO_MODE_OUTPUT;
  GPIO_InitStruct.Speed = LL_GPIO_SPEED_FREQ_HIGH;
  GPIO_InitStruct.OutputType = LL_GPIO_OUTPUT_PUSHPULL;
  GPIO_InitStruct.Pull = LL_GPIO_PULL_UP;
  LL_GPIO_Init(TOUCH_CS_GPIO_Port, &GPIO_InitStruct);

  /**/
  LL_SYSCFG_SetEXTISource(LL_SYSCFG_EXTI_PORTC, LL_SYSCFG_EXTI_LINE14);

  /**/
  LL_SYSCFG_SetEXTISource(LL_SYSCFG_EXTI_PORTA, LL_SYSCFG_EXTI_LINE0);

  /**/
  LL_SYSCFG_SetEXTISource(LL_SYSCFG_EXTI_PORTA, LL_SYSCFG_EXTI_LINE1);

  /**/
  LL_SYSCFG_SetEXTISource(LL_SYSCFG_EXTI_PORTD, LL_SYSCFG_EXTI_LINE6);

  /**/
  EXTI_InitStruct.Line_0_31 = LL_EXTI_LINE_14;
  EXTI_InitStruct.LineCommand = ENABLE;
  EXTI_InitStruct.Mode = LL_EXTI_MODE_IT;
  EXTI_InitStruct.Trigger = LL_EXTI_TRIGGER_FALLING;
  LL_EXTI_Init(&EXTI_InitStruct);

  /**/
  EXTI_InitStruct.Line_0_31 = LL_EXTI_LINE_0;
  EXTI_InitStruct.LineCommand = ENABLE;
  EXTI_InitStruct.Mode = LL_EXTI_MODE_IT;
  EXTI_InitStruct.Trigger = LL_EXTI_TRIGGER_FALLING;
  LL_EXTI_Init(&EXTI_InitStruct);

  /**/
  EXTI_InitStruct.Line_0_31 = LL_EXTI_LINE_1;
  EXTI_InitStruct.LineCommand = ENABLE;
  EXTI_InitStruct.Mode = LL_EXTI_MODE_IT;
  EXTI_InitStruct.Trigger = LL_EXTI_TRIGGER_FALLING;
  LL_EXTI_Init(&EXTI_InitStruct);

  /**/
  EXTI_InitStruct.Line_0_31 = LL_EXTI_LINE_6;
  EXTI_InitStruct.LineCommand = ENABLE;
  EXTI_InitStruct.Mode = LL_EXTI_MODE_IT;
  EXTI_InitStruct.Trigger = LL_EXTI_TRIGGER_FALLING;
  LL_EXTI_Init(&EXTI_InitStruct);

  /**/
  LL_GPIO_SetPinPull(BTN_ESC_GPIO_Port, BTN_ESC_Pin, LL_GPIO_PULL_UP);

  /**/
  LL_GPIO_SetPinPull(adc_Int_GPIO_Port, adc_Int_Pin, LL_GPIO_PULL_UP);

  /**/
  LL_GPIO_SetPinPull(MPU_INT_GPIO_Port, MPU_INT_Pin, LL_GPIO_PULL_NO);

  /**/
  LL_GPIO_SetPinPull(TOUCH_IRQ_GPIO_Port, TOUCH_IRQ_Pin, LL_GPIO_PULL_UP);

  /**/
  LL_GPIO_SetPinMode(BTN_ESC_GPIO_Port, BTN_ESC_Pin, LL_GPIO_MODE_INPUT);

  /**/
  LL_GPIO_SetPinMode(adc_Int_GPIO_Port, adc_Int_Pin, LL_GPIO_MODE_INPUT);

  /**/
  LL_GPIO_SetPinMode(MPU_INT_GPIO_Port, MPU_INT_Pin, LL_GPIO_MODE_INPUT);

  /**/
  LL_GPIO_SetPinMode(TOUCH_IRQ_GPIO_Port, TOUCH_IRQ_Pin, LL_GPIO_MODE_INPUT);

  /* EXTI interrupt init*/
  NVIC_SetPriority(EXTI0_IRQn, NVIC_EncodePriority(NVIC_GetPriorityGrouping(),1, 0));
  NVIC_EnableIRQ(EXTI0_IRQn);
  NVIC_SetPriority(EXTI1_IRQn, NVIC_EncodePriority(NVIC_GetPriorityGrouping(),1, 0));
  NVIC_EnableIRQ(EXTI1_IRQn);
  NVIC_SetPriority(EXTI9_5_IRQn, NVIC_EncodePriority(NVIC_GetPriorityGrouping(),0, 0));
  NVIC_EnableIRQ(EXTI9_5_IRQn);
  NVIC_SetPriority(EXTI15_10_IRQn, NVIC_EncodePriority(NVIC_GetPriorityGrouping(),0, 0));
  NVIC_EnableIRQ(EXTI15_10_IRQn);

}

void Error_Handler(void)
{
  __disable_irq();
  while (1)
  {
  }
}
